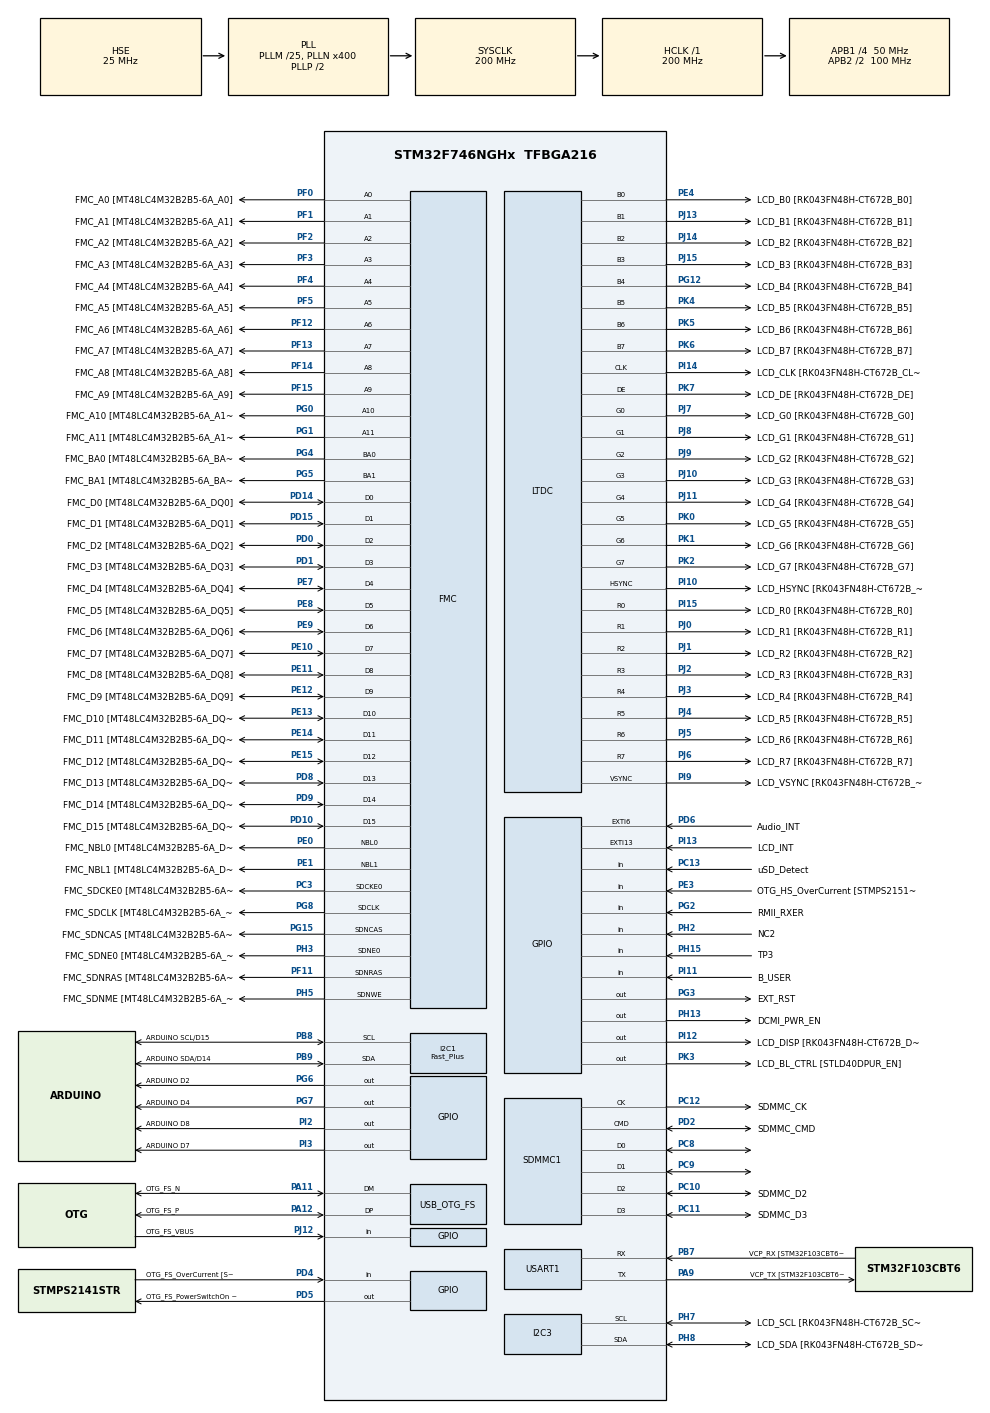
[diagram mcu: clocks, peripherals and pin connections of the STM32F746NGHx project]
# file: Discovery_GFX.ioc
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CORTEX_M7.ART_ACCLERATOR_ENABLE=1
CORTEX_M7.CPU_DCache=Enabled
CORTEX_M7.CPU_ICache=Enabled
CORTEX_M7.FlashInterface=TCM_Enabled
CORTEX_M7.PREFETCH_ENABLE=1
FATFS.BSP.number=1
FATFS._FS_EXFAT=1
FATFS._FS_NORTC=1
FATFS._LFN_UNICODE=0
FATFS._MAX_SS=4096
FATFS._NORTC_MDAY=1
FATFS._NORTC_MON=1
FATFS._NORTC_YEAR=2019
FATFS._STRF_ENCODE=0
FATFS._USE_EXPAND=1
FATFS._USE_FIND=1
FATFS._USE_FORWARD=1
FATFS._USE_LFN=3
FATFS._USE_MKFS=0
FATFS0.BSP.STBoard=false
FATFS0.BSP.api=Unknown
FATFS0.BSP.i2caddr=0
FATFS0.BSP.instance=PC13
FATFS0.BSP.ip=GPIO
FATFS0.BSP.mode=Input
FATFS0.BSP.name=Detect_SDIO
FATFS0.BSP.solution=PC13
FMC.CASLatency1=FMC_SDRAM_CAS_LATENCY_3
FMC.ExitSelfRefreshDelay1=7
FMC.LoadToActiveDelay1=2
FMC.RCDDelay1=2
FMC.RPDelay1=2
FMC.RPDelay2=2
FMC.ReadBurst1=FMC_SDRAM_RBURST_ENABLE
FMC.ReadBurst2=FMC_SDRAM_RBURST_ENABLE
FMC.RowCycleDelay1=6
FMC.RowCycleDelay2=6
FMC.SDClockPeriod1=FMC_SDRAM_CLOCK_PERIOD_2
FMC.SDClockPeriod2=FMC_SDRAM_CLOCK_PERIOD_2
FMC.SelfRefreshTime1=4
FMC.WriteRecoveryTime1=2
GRAPHICS.BSP.number=1
GRAPHICS.Check_OTM8009A_PixelFormat-STemWin=1
GRAPHICS.DMA2D_Graphics-STemWin=1
GRAPHICS.EA_1_Apptype=Window
GRAPHICS.EA_1_executable_name-STemWin=GUIBuilder.exe
GRAPHICS.GUI_NUM_LAYERS-STemWin=1
GRAPHICS.GUI_Num_KBYTES=64
GRAPHICS.GUI_RGB_ORDERING=ABGR
GRAPHICS.LIN_Color_Conversion_Layer0=GUICC_M8888I
GRAPHICS.LIN_Color_Conversion_Layer1=GUICC_M8888I
GRAPHICS.LIN_Color_Conversion_Layer1-STemWin=0
GRAPHICS.LIN_Frame_Buffer_Depth_Layer0-STemWin=32
GRAPHICS.LIN_Frame_Buffer_Depth_Layer1-STemWin=32
GRAPHICS.Num_MultBuffers=1
GRAPHICS.OPTIM_OS_use-STemWin=5
GRAPHICS.USE_Embedded_Wizard-STemWin=0
GRAPHICS.USE_STTouchGFX-STemWin=0
GRAPHICS.UseGUIBuilder=Enabled
GRAPHICS.Use_SDRAM-STemWin=SDRAM1_BANK1
GRAPHICS.Xsize_PHYS=480
GRAPHICS.Ysize_PHYS=272
GRAPHICS0.BSP.STBoard=false
GRAPHICS0.BSP.api=Unknown
GRAPHICS0.BSP.i2caddr=0
GRAPHICS0.BSP.instance=PG3
GRAPHICS0.BSP.ip=GPIO
GRAPHICS0.BSP.mode=Output
GRAPHICS0.BSP.name=LCD Reset Pin XRES
GRAPHICS0.BSP.solution=PG3
I2C1.I2C_Speed_Mode=I2C_Fast_Plus
I2C1.Timing=0x0020081F
I2C3.Timing=0x00C0EAFF
LTDC.ActiveH=272
LTDC.ActiveW=480
LTDC.Alpha_L0=255
LTDC.Alpha_L1=255
LTDC.BlendingFactor1_L0=LTDC_BLENDING_FACTOR1_PAxCA
LTDC.BlendingFactor1_L1=LTDC_BLENDING_FACTOR1_PAxCA
LTDC.BlendingFactor2_L0=LTDC_BLENDING_FACTOR2_PAxCA
LTDC.BlendingFactor2_L1=LTDC_BLENDING_FACTOR2_PAxCA
LTDC.FBStartAdress_L0=0xC0000000
LTDC.FBStartAdress_L1=0xC0100000
LTDC.HBP=13
LTDC.HFP=32
LTDC.HSync=41
LTDC.ImageHeight_L0=272
LTDC.ImageHeight_L1=272
LTDC.ImageWidth_L0=480
LTDC.ImageWidth_L1=480
LTDC.Layers=0
LTDC.PixelFormat_L0=LTDC_PIXEL_FORMAT_ARGB8888
LTDC.PixelFormat_L1=LTDC_PIXEL_FORMAT_ARGB8888
LTDC.VSync=10
LTDC.WindowX1_L0=480
LTDC.WindowX1_L1=480
LTDC.WindowY1_L0=272
LTDC.WindowY1_L1=272
Mcu.Family=STM32F7
Mcu.Name=STM32F746NGHx
Mcu.Package=TFBGA216
NVIC.DMA2D_IRQn=true\:1\:0\:true\:false\:true\:true\:true
NVIC.LTDC_IRQn=true\:2\:0\:true\:false\:true\:true\:true
NVIC.OTG_FS_IRQn=true\:7\:0\:true\:false\:true\:false\:true
NVIC.PriorityGroup=NVIC_PRIORITYGROUP_4
NVIC.SDMMC1_IRQn=true\:6\:0\:true\:false\:true\:true\:true
NVIC.TIM3_IRQn=true\:10\:0\:true\:false\:true\:true\:true
NVIC.TIM6_DAC_IRQn=true\:0\:0\:false\:false\:true\:false\:true
NVIC.TimeBase=TIM6_DAC_IRQn
NVIC.TimeBaseIP=TIM6
PA0/WKUP.GPIO_Label=ARDUINO A0
PA0/WKUP.GPIO_Mode=GPIO_MODE_ANALOG
PA0/WKUP.GPIO_PuPd=GPIO_NOPULL
PA0/WKUP.Signal=ADCx_IN0
PA1.GPIO_Label=RMII_REF_CLK [LAN8742A-CZ-TR_REFCLK0]
PA1.Signal=ETH_REF_CLK
PA10.GPIO_Label=OTG_FS_ID
PA10.Signal=USB_OTG_FS_ID
PA11.GPIO_Label=OTG_FS_N
PA11.Mode=Device_Only
PA11.Signal=USB_OTG_FS_DM
PA12.GPIO_Label=OTG_FS_P
PA12.Mode=Device_Only
PA12.Signal=USB_OTG_FS_DP
PA13.GPIO_Label=SWDIO
PA13.Mode=Serial_Wire
PA13.Signal=SYS_JTMS-SWDIO
PA14.GPIO_Label=SWCLK
PA14.Mode=Serial_Wire
PA14.Signal=SYS_JTCK-SWCLK
PA15.GPIO_Label=ARDUINO PWM/D9
PA15.GPIO_ModeDefaultPP=GPIO_MODE_AF_PP
PA15.GPIO_PuPd=GPIO_NOPULL
PA15.GPIO_Speed=GPIO_SPEED_FREQ_VERY_HIGH
PA15.Signal=S_TIM2_CH1_ETR
PA2.GPIO_Label=RMII_MDIO [LAN8742A-CZ-TR_MDIO]
PA2.Signal=ETH_MDIO
PA3.GPIO_Label=ULPI_D0 [USB3320C-EZK_D0]
PA3.Signal=USB_OTG_HS_ULPI_D0
PA4.GPIO_Label=DCMI_HSYNC
PA4.GPIO_Speed=GPIO_SPEED_FREQ_VERY_HIGH
PA4.Signal=DCMI_HSYNC
PA5.GPIO_Label=ULPI_CLK [USB3320C-EZK_CLKOUT]
PA5.Signal=USB_OTG_HS_ULPI_CK
PA6.GPIO_Speed=GPIO_SPEED_FREQ_VERY_HIGH
PA6.Signal=DCMI_PIXCLK
PA7.GPIO_Label=RMII_CRS_DV [LAN8742A-CZ-TR_CRS_DV]
PA7.Signal=ETH_CRS_DV
PA8.GPIO_Label=ARDUINO PWM/D10
PA8.GPIO_ModeDefaultPP=GPIO_MODE_AF_PP
PA8.GPIO_PuPd=GPIO_NOPULL
PA8.GPIO_Speed=GPIO_SPEED_FREQ_VERY_HIGH
PA8.Signal=S_TIM1_CH1
PA9.GPIO_Label=VCP_TX [STM32F103CBT6_PA3]
PA9.GPIO_Mode=GPIO_MODE_AF_PP
PA9.GPIO_PuPd=GPIO_NOPULL
PA9.GPIO_Speed=GPIO_SPEED_FREQ_LOW
PA9.Mode=Asynchronous
PA9.Signal=USART1_TX
PB0.GPIO_Label=ULPI_D1 [USB3320C-EZK_D1]
PB0.Signal=USB_OTG_HS_ULPI_D1
PB1.GPIO_Label=ULPI_D2 [USB3320C-EZK_D2]
PB1.Signal=USB_OTG_HS_ULPI_D2
PB10.GPIO_Label=ULPI_D3 [USB3320C-EZK_D3]
PB10.Signal=USB_OTG_HS_ULPI_D3
PB11.GPIO_Label=ULPI_D4 [USB3320C-EZK_D4]
PB11.Signal=USB_OTG_HS_ULPI_D4
PB12.GPIO_Label=ULPI_D5 [USB3320C-EZK_D5]
PB12.Signal=USB_OTG_HS_ULPI_D5
PB13.GPIO_Label=ULPI_D6 [USB3320C-EZK_D6]
PB13.Signal=USB_OTG_HS_ULPI_D6
PB14.GPIO_Label=ARDUINO MISO/D12
PB14.GPIO_Mode=GPIO_MODE_AF_PP
PB14.GPIO_PuPd=GPIO_NOPULL
PB14.GPIO_Speed=GPIO_SPEED_FREQ_LOW
PB14.Signal=SPI2_MISO
PB15.GPIO_Label=ARDUINO MOSI/PWM/D11
PB15.GPIO_Mode=GPIO_MODE_AF_PP
PB15.GPIO_PuPd=GPIO_NOPULL
PB15.GPIO_Speed=GPIO_SPEED_FREQ_LOW
PB15.Signal=SPI2_MOSI
PB2.Signal=QUADSPI_CLK
PB3.GPIO_Label=SWO
PB3.Signal=SYS_JTDO-SWO
PB4.GPIO_Label=ARDUINO PWM/D3
PB4.GPIO_ModeDefaultPP=GPIO_MODE_AF_PP
PB4.GPIO_PuPd=GPIO_NOPULL
PB4.GPIO_Speed=GPIO_SPEED_FREQ_LOW
PB4.Signal=S_TIM3_CH1
PB5.GPIO_Label=ULPI_D7 [USB3320C-EZK_D7]
PB5.Signal=USB_OTG_HS_ULPI_D7
PB6.GPIO_Label=QSPI_NCS [N25Q128A13EF840E_S]
PB6.Signal=QUADSPI_BK1_NCS
PB7.GPIO_Label=VCP_RX [STM32F103CBT6_PA2]
PB7.GPIO_Mode=GPIO_MODE_AF_PP
PB7.GPIO_PuPd=GPIO_NOPULL
PB7.GPIO_Speed=GPIO_SPEED_FREQ_LOW
PB7.Mode=Asynchronous
PB7.Signal=USART1_RX
PB8.GPIO_Label=ARDUINO SCL/D15
PB8.GPIO_Mode=GPIO_MODE_AF_OD
PB8.GPIO_PuPd=GPIO_NOPULL
PB8.GPIO_Speed=GPIO_SPEED_FREQ_LOW
PB8.Mode=I2C
PB8.Signal=I2C1_SCL
PB9.GPIO_Label=ARDUINO SDA/D14
PB9.GPIO_Mode=GPIO_MODE_AF_OD
PB9.GPIO_PuPd=GPIO_NOPULL
PB9.GPIO_Speed=GPIO_SPEED_FREQ_LOW
PB9.Mode=I2C
PB9.Signal=I2C1_SDA
PC0.GPIO_Label=ULPI_STP [USB3320C-EZK_STP]
PC0.Signal=USB_OTG_HS_ULPI_STP
PC1.GPIO_Label=RMII_MDC [LAN8742A-CZ-TR_MDC]
PC1.Signal=ETH_MDC
PC10.GPIO_Label=SDMMC_D2
PC10.Mode=SD_4_bits_Wide_bus
PC10.Signal=SDMMC1_D2
PC11.GPIO_Label=SDMMC_D3
PC11.Mode=SD_4_bits_Wide_bus
PC11.Signal=SDMMC1_D3
PC12.GPIO_Label=SDMMC_CK
PC12.Mode=SD_4_bits_Wide_bus
PC12.Signal=SDMMC1_CK
PC13.GPIO_Label=uSD_Detect
PC13.Signal=GPIO_Input
PC14/OSC32_IN.GPIO_Label=RCC_OSC32_IN
PC14/OSC32_IN.Signal=RCC_OSC32_IN
PC15/OSC32_OUT.GPIO_Label=RCC_OSC32_OUT
PC15/OSC32_OUT.Signal=RCC_OSC32_OUT
PC2.GPIO_Label=ULPI_DIR [USB3320C-EZK_DIR]
PC2.Signal=USB_OTG_HS_ULPI_DIR
PC3.GPIO_Label=FMC_SDCKE0 [MT48LC4M32B2B5-6A_CKE]
PC3.Mode=SdramChipSelect1_1
PC3.Signal=FMC_SDCKE0
PC4.GPIO_Label=RMII_RXD0 [LAN8742A-CZ-TR_RXD0]
PC4.Signal=ETH_RXD0
PC5.GPIO_Label=RMII_RXD1 [LAN8742A-CZ-TR_RXD1]
PC5.Signal=ETH_RXD1
PC6.GPIO_Label=ARDUINO TX/D1
PC6.Signal=USART6_TX
PC7.GPIO_Label=ARDUINO RX/D0
PC7.Signal=USART6_RX
PC8.Mode=SD_4_bits_Wide_bus
PC8.Signal=SDMMC1_D0
PC9.Mode=SD_4_bits_Wide_bus
PC9.Signal=SDMMC1_D1
PD0.GPIO_Label=FMC_D2 [MT48LC4M32B2B5-6A_DQ2]
PD0.Signal=FMC_D2_DA2
PD1.GPIO_Label=FMC_D3 [MT48LC4M32B2B5-6A_DQ3]
PD1.Signal=FMC_D3_DA3
PD10.GPIO_Label=FMC_D15 [MT48LC4M32B2B5-6A_DQ15]
PD10.Signal=FMC_D15_DA15
PD11.GPIO_Label=QSPI_D0 [N25Q128A13EF840E_DQ0]
PD11.Signal=QUADSPI_BK1_IO0
PD12.GPIO_Label=QSPI_D1 [N25Q128A13EF840E_DQ1]
PD12.Signal=QUADSPI_BK1_IO1
PD13.GPIO_Label=QSPI_D3 [N25Q128A13EF840E_DQ3]
PD13.Signal=QUADSPI_BK1_IO3
PD14.GPIO_Label=FMC_D0 [MT48LC4M32B2B5-6A_DQ0]
PD14.Signal=FMC_D0_DA0
PD15.GPIO_Label=FMC_D1 [MT48LC4M32B2B5-6A_DQ1]
PD15.Signal=FMC_D1_DA1
PD2.GPIO_Label=SDMMC_CMD
PD2.Mode=SD_4_bits_Wide_bus
PD2.Signal=SDMMC1_CMD
PD3.GPIO_Label=DCMI_D5
PD3.GPIO_Speed=GPIO_SPEED_FREQ_VERY_HIGH
PD3.Signal=DCMI_D5
PD4.GPIO_Label=OTG_FS_OverCurrent [STMPS2141STR_Fault]
PD4.Signal=GPIO_Input
PD5.GPIO_Label=OTG_FS_PowerSwitchOn [STMPS2141STR_EN]
PD5.PinState=GPIO_PIN_SET
PD5.Signal=GPIO_Output
PD6.GPIO_Label=Audio_INT
PD6.GPIO_ModeDefaultEXTI=GPIO_MODE_EVT_RISING
PD6.Signal=GPXTI6
PD7.GPIO_Label=SPDIF_RX0 [74LVC1G04SE_4]
PD7.Signal=SPDIFRX_IN0
PD8.GPIO_Label=FMC_D13 [MT48LC4M32B2B5-6A_DQ13]
PD8.Signal=FMC_D13_DA13
PD9.GPIO_Label=FMC_D14 [MT48LC4M32B2B5-6A_DQ14]
PD9.Signal=FMC_D14_DA14
PE0.GPIO_Label=FMC_NBL0 [MT48LC4M32B2B5-6A_DQM0]
PE0.Signal=FMC_NBL0
PE1.GPIO_Label=FMC_NBL1 [MT48LC4M32B2B5-6A_DQM1]
PE1.Signal=FMC_NBL1
PE10.GPIO_Label=FMC_D7 [MT48LC4M32B2B5-6A_DQ7]
PE10.Signal=FMC_D7_DA7
PE11.GPIO_Label=FMC_D8 [MT48LC4M32B2B5-6A_DQ8]
PE11.Signal=FMC_D8_DA8
PE12.GPIO_Label=FMC_D9 [MT48LC4M32B2B5-6A_DQ9]
PE12.Signal=FMC_D9_DA9
PE13.GPIO_Label=FMC_D10 [MT48LC4M32B2B5-6A_DQ10]
PE13.Signal=FMC_D10_DA10
PE14.GPIO_Label=FMC_D11 [MT48LC4M32B2B5-6A_DQ11]
PE14.Signal=FMC_D11_DA11
PE15.GPIO_Label=FMC_D12 [MT48LC4M32B2B5-6A_DQ12]
PE15.Signal=FMC_D12_DA12
PE2.GPIO_Label=QSPI_D2 [N25Q128A13EF840E_DQ2]
PE2.Signal=QUADSPI_BK1_IO2
PE3.GPIO_Label=OTG_HS_OverCurrent [STMPS2151STR_FAULT]
PE3.Signal=GPIO_Input
PE4.GPIO_Label=LCD_B0 [RK043FN48H-CT672B_B0]
PE4.GPIO_Speed=GPIO_SPEED_FREQ_VERY_HIGH
PE4.Mode=RGB888
PE4.Signal=LTDC_B0
PE5.GPIO_Label=DCMI_D6
PE5.GPIO_Speed=GPIO_SPEED_FREQ_VERY_HIGH
PE5.Signal=DCMI_D6
PE6.GPIO_Label=DCMI_D7
PE6.GPIO_Speed=GPIO_SPEED_FREQ_VERY_HIGH
PE6.Signal=DCMI_D7
PE7.GPIO_Label=FMC_D4 [MT48LC4M32B2B5-6A_DQ4]
PE7.Signal=FMC_D4_DA4
PE8.GPIO_Label=FMC_D5 [MT48LC4M32B2B5-6A_DQ5]
PE8.Signal=FMC_D5_DA5
PE9.GPIO_Label=FMC_D6 [MT48LC4M32B2B5-6A_DQ6]
PE9.Signal=FMC_D6_DA6
PF0.GPIO_Label=FMC_A0 [MT48LC4M32B2B5-6A_A0]
PF0.Signal=FMC_A0
PF1.GPIO_Label=FMC_A1 [MT48LC4M32B2B5-6A_A1]
PF1.Signal=FMC_A1
PF10.GPIO_Label=ARDUINO A1
PF10.GPIO_Mode=GPIO_MODE_ANALOG
PF10.GPIO_PuPd=GPIO_NOPULL
PF10.Signal=ADC3_IN8
PF11.GPIO_Label=FMC_SDNRAS [MT48LC4M32B2B5-6A_RAS]
PF11.Signal=FMC_SDNRAS
PF12.GPIO_Label=FMC_A6 [MT48LC4M32B2B5-6A_A6]
PF12.Signal=FMC_A6
PF13.GPIO_Label=FMC_A7 [MT48LC4M32B2B5-6A_A7]
PF13.Signal=FMC_A7
PF14.GPIO_Label=FMC_A8 [MT48LC4M32B2B5-6A_A8]
PF14.Signal=FMC_A8
PF15.GPIO_Label=FMC_A9 [MT48LC4M32B2B5-6A_A9]
PF15.Signal=FMC_A9
PF2.GPIO_Label=FMC_A2 [MT48LC4M32B2B5-6A_A2]
PF2.Signal=FMC_A2
PF3.GPIO_Label=FMC_A3 [MT48LC4M32B2B5-6A_A3]
PF3.Signal=FMC_A3
PF4.GPIO_Label=FMC_A4 [MT48LC4M32B2B5-6A_A4]
PF4.Signal=FMC_A4
PF5.GPIO_Label=FMC_A5 [MT48LC4M32B2B5-6A_A5]
PF5.Signal=FMC_A5
PF6.GPIO_Label=ARDUINO A5
PF6.GPIO_Mode=GPIO_MODE_ANALOG
PF6.GPIO_PuPd=GPIO_NOPULL
PF6.Signal=ADC3_IN4
PF7.GPIO_Label=ARDUINO A4
PF7.GPIO_Mode=GPIO_MODE_ANALOG
PF7.GPIO_PuPd=GPIO_NOPULL
PF7.Signal=ADC3_IN5
PF8.GPIO_Label=ARDUINO A3
PF8.GPIO_Mode=GPIO_MODE_ANALOG
PF8.GPIO_PuPd=GPIO_NOPULL
PF8.Signal=ADC3_IN6
PF9.GPIO_Label=ARDUINO A2
PF9.GPIO_Mode=GPIO_MODE_ANALOG
PF9.GPIO_PuPd=GPIO_NOPULL
PF9.Signal=ADC3_IN7
PG0.GPIO_Label=FMC_A10 [MT48LC4M32B2B5-6A_A10]
PG0.Signal=FMC_A10
PG1.GPIO_Label=FMC_A11 [MT48LC4M32B2B5-6A_A11]
PG1.Signal=FMC_A11
PG10.GPIO_Label=SAI2_SDB [WM8994ECS/R_ADCDAT1]
PG10.Signal=SAI2_SD_B
PG11.GPIO_Label=RMII_TX_EN [LAN8742A-CZ-TR_TXEN]
PG11.Signal=ETH_TX_EN
PG12.GPIO_Label=LCD_B4 [RK043FN48H-CT672B_B4]
PG12.GPIO_Speed=GPIO_SPEED_FREQ_VERY_HIGH
PG12.Mode=RGB888
PG12.Signal=LTDC_B4
PG13.GPIO_Label=RMII_TXD0 [LAN8742A-CZ-TR_TXD0]
PG13.Signal=ETH_TXD0
PG14.GPIO_Label=RMII_TXD1 [LAN8742A-CZ-TR_TXD1]
PG14.Signal=ETH_TXD1
PG15.GPIO_Label=FMC_SDNCAS [MT48LC4M32B2B5-6A_CAS]
PG15.Signal=FMC_SDNCAS
PG2.GPIO_Label=RMII_RXER
PG2.Signal=GPIO_Input
PG3.GPIO_Label=EXT_RST
PG3.Signal=GPIO_Output
PG4.GPIO_Label=FMC_BA0 [MT48LC4M32B2B5-6A_BA0]
PG4.Signal=FMC_A14_BA0
PG5.GPIO_Label=FMC_BA1 [MT48LC4M32B2B5-6A_BA1]
PG5.Signal=FMC_A15_BA1
PG6.GPIO_Label=ARDUINO D2
PG6.Signal=GPIO_Output
PG7.GPIO_Label=ARDUINO D4
PG7.Signal=GPIO_Output
PG8.GPIO_Label=FMC_SDCLK [MT48LC4M32B2B5-6A_CLK]
PG8.Signal=FMC_SDCLK
PG9.GPIO_Label=DCMI_VSYNC
PG9.GPIO_Speed=GPIO_SPEED_FREQ_VERY_HIGH
PG9.Signal=DCMI_VSYNC
PH0/OSC_IN.GPIO_Label=OSC_25M [NZ2520SB-25.00M_OUT]
PH0/OSC_IN.Mode=HSE-External-Oscillator
PH0/OSC_IN.Signal=RCC_OSC_IN
PH1/OSC_OUT.Mode=HSE-External-Oscillator
PH1/OSC_OUT.Signal=RCC_OSC_OUT
PH10.GPIO_Label=DCMI_D1
PH10.GPIO_Speed=GPIO_SPEED_FREQ_VERY_HIGH
PH10.Signal=DCMI_D1
PH11.GPIO_Label=DCMI_D2
PH11.GPIO_Speed=GPIO_SPEED_FREQ_VERY_HIGH
PH11.Signal=DCMI_D2
PH12.GPIO_Label=DCMI_D3
PH12.GPIO_Speed=GPIO_SPEED_FREQ_VERY_HIGH
PH12.Signal=DCMI_D3
PH13.GPIO_Label=DCMI_PWR_EN
PH13.Signal=GPIO_Output
PH14.GPIO_Label=DCMI_D4
PH14.GPIO_Speed=GPIO_SPEED_FREQ_VERY_HIGH
PH14.Signal=DCMI_D4
PH15.GPIO_Label=TP3
PH15.Signal=GPIO_Input
PH2.GPIO_Label=NC2
PH2.Signal=GPIO_Input
PH3.GPIO_Label=FMC_SDNE0 [MT48LC4M32B2B5-6A_CS]
PH3.Mode=SdramChipSelect1_1
PH3.Signal=FMC_SDNE0
PH4.GPIO_Label=ULPI_NXT [USB3320C-EZK_NXT]
PH4.Signal=USB_OTG_HS_ULPI_NXT
PH5.GPIO_Label=FMC_SDNME [MT48LC4M32B2B5-6A_WE]
PH5.Signal=FMC_SDNWE
PH6.GPIO_Label=ARDUINO PWM/D6
PH6.Signal=S_TIM12_CH1
PH7.GPIO_Label=LCD_SCL [RK043FN48H-CT672B_SCL]
PH7.Mode=I2C
PH7.Signal=I2C3_SCL
PH8.GPIO_Label=LCD_SDA [RK043FN48H-CT672B_SDA]
PH8.Mode=I2C
PH8.Signal=I2C3_SDA
PH9.GPIO_Label=DCMI_D0
PH9.GPIO_Speed=GPIO_SPEED_FREQ_VERY_HIGH
PH9.Signal=DCMI_D0
PI0.GPIO_Label=ARDUINO PWM/CS/D5
PI0.GPIO_ModeDefaultPP=GPIO_MODE_AF_PP
PI0.GPIO_PuPd=GPIO_NOPULL
PI0.GPIO_Speed=GPIO_SPEED_FREQ_LOW
PI0.Signal=S_TIM5_CH4
PI1.GPIO_Label=ARDUINO SCK/D13
PI1.GPIO_Mode=GPIO_MODE_AF_PP
PI1.GPIO_PuPd=GPIO_NOPULL
PI1.GPIO_Speed=GPIO_SPEED_FREQ_LOW
PI1.Signal=SPI2_SCK
PI10.GPIO_Label=LCD_HSYNC [RK043FN48H-CT672B_HSYNC]
PI10.GPIO_Speed=GPIO_SPEED_FREQ_VERY_HIGH
PI10.Mode=RGB888
PI10.Signal=LTDC_HSYNC
PI11.GPIO_Label=B_USER
PI11.Signal=GPIO_Input
PI12.GPIO_Label=LCD_DISP [RK043FN48H-CT672B_DISP] 
PI12.PinState=GPIO_PIN_SET
PI12.Signal=GPIO_Output
PI13.GPIO_Label=LCD_INT
PI13.GPIO_ModeDefaultEXTI=GPIO_MODE_EVT_RISING
PI13.Signal=GPXTI13
PI14.GPIO_Label=LCD_CLK [RK043FN48H-CT672B_CLK]
PI14.GPIO_Speed=GPIO_SPEED_FREQ_VERY_HIGH
PI14.Mode=RGB888
PI14.Signal=LTDC_CLK
PI15.GPIO_Label=LCD_R0 [RK043FN48H-CT672B_R0]
PI15.GPIO_Speed=GPIO_SPEED_FREQ_VERY_HIGH
PI15.Mode=RGB888
PI15.Signal=LTDC_R0
PI2.GPIO_Label=ARDUINO D8
PI2.Signal=GPIO_Output
PI3.GPIO_Label=ARDUINO D7
PI3.Signal=GPIO_Output
PI4.GPIO_Label=SAI2_MCLKA [WM8994ECS/R_MCLK1]
PI4.Signal=SAI2_MCLK_A
PI5.GPIO_Label=SAI2_SCKA [WM8994ECS/R_BCLK1]
PI5.Signal=SAI2_SCK_A
PI6.GPIO_Label=SAI2_SDA [WM8994ECS/R_DACDAT1]
PI6.Signal=SAI2_SD_A
PI7.GPIO_Label=SAI2_FSA [WM8994ECS/R_LRCLK1]
PI7.Signal=SAI2_FS_A
PI8.GPIO_Label=NC1 [TP2]
PI8.Signal=RTC_TS
PI9.GPIO_Label=LCD_VSYNC [RK043FN48H-CT672B_VSYNC]
PI9.GPIO_Speed=GPIO_SPEED_FREQ_VERY_HIGH
PI9.Mode=RGB888
PI9.Signal=LTDC_VSYNC
PJ0.GPIO_Label=LCD_R1 [RK043FN48H-CT672B_R1]
PJ0.GPIO_Speed=GPIO_SPEED_FREQ_VERY_HIGH
PJ0.Mode=RGB888
PJ0.Signal=LTDC_R1
PJ1.GPIO_Label=LCD_R2 [RK043FN48H-CT672B_R2]
PJ1.GPIO_Speed=GPIO_SPEED_FREQ_VERY_HIGH
PJ1.Mode=RGB888
PJ1.Signal=LTDC_R2
PJ10.GPIO_Label=LCD_G3 [RK043FN48H-CT672B_G3]
PJ10.GPIO_Speed=GPIO_SPEED_FREQ_VERY_HIGH
PJ10.Mode=RGB888
PJ10.Signal=LTDC_G3
PJ11.GPIO_Label=LCD_G4 [RK043FN48H-CT672B_G4]
PJ11.GPIO_Speed=GPIO_SPEED_FREQ_VERY_HIGH
PJ11.Mode=RGB888
PJ11.Signal=LTDC_G4
PJ12.GPIO_Label=OTG_FS_VBUS
PJ12.Signal=GPIO_Input
PJ13.GPIO_Label=LCD_B1 [RK043FN48H-CT672B_B1]
PJ13.GPIO_Speed=GPIO_SPEED_FREQ_VERY_HIGH
PJ13.Mode=RGB888
PJ13.Signal=LTDC_B1
PJ14.GPIO_Label=LCD_B2 [RK043FN48H-CT672B_B2]
PJ14.GPIO_Speed=GPIO_SPEED_FREQ_VERY_HIGH
PJ14.Mode=RGB888
PJ14.Signal=LTDC_B2
PJ15.GPIO_Label=LCD_B3 [RK043FN48H-CT672B_B3]
PJ15.GPIO_Speed=GPIO_SPEED_FREQ_VERY_HIGH
PJ15.Mode=RGB888
PJ15.Signal=LTDC_B3
PJ2.GPIO_Label=LCD_R3 [RK043FN48H-CT672B_R3]
PJ2.GPIO_Speed=GPIO_SPEED_FREQ_VERY_HIGH
PJ2.Mode=RGB888
PJ2.Signal=LTDC_R3
PJ3.GPIO_Label=LCD_R4 [RK043FN48H-CT672B_R4]
PJ3.GPIO_Speed=GPIO_SPEED_FREQ_VERY_HIGH
PJ3.Mode=RGB888
PJ3.Signal=LTDC_R4
PJ4.GPIO_Label=LCD_R5 [RK043FN48H-CT672B_R5]
PJ4.GPIO_Speed=GPIO_SPEED_FREQ_VERY_HIGH
PJ4.Mode=RGB888
PJ4.Signal=LTDC_R5
PJ5.GPIO_Label=LCD_R6 [RK043FN48H-CT672B_R6]
PJ5.GPIO_Speed=GPIO_SPEED_FREQ_VERY_HIGH
PJ5.Mode=RGB888
PJ5.Signal=LTDC_R6
PJ6.GPIO_Label=LCD_R7 [RK043FN48H-CT672B_R7]
PJ6.GPIO_Speed=GPIO_SPEED_FREQ_VERY_HIGH
PJ6.Mode=RGB888
PJ6.Signal=LTDC_R7
PJ7.GPIO_Label=LCD_G0 [RK043FN48H-CT672B_G0]
PJ7.GPIO_Speed=GPIO_SPEED_FREQ_VERY_HIGH
PJ7.Mode=RGB888
PJ7.Signal=LTDC_G0
PJ8.GPIO_Label=LCD_G1 [RK043FN48H-CT672B_G1]
PJ8.GPIO_Speed=GPIO_SPEED_FREQ_VERY_HIGH
PJ8.Mode=RGB888
PJ8.Signal=LTDC_G1
PJ9.GPIO_Label=LCD_G2 [RK043FN48H-CT672B_G2]
PJ9.GPIO_Speed=GPIO_SPEED_FREQ_VERY_HIGH
PJ9.Mode=RGB888
PJ9.Signal=LTDC_G2
PK0.GPIO_Label=LCD_G5 [RK043FN48H-CT672B_G5]
PK0.GPIO_Speed=GPIO_SPEED_FREQ_VERY_HIGH
PK0.Mode=RGB888
PK0.Signal=LTDC_G5
PK1.GPIO_Label=LCD_G6 [RK043FN48H-CT672B_G6]
PK1.GPIO_Speed=GPIO_SPEED_FREQ_VERY_HIGH
PK1.Mode=RGB888
PK1.Signal=LTDC_G6
PK2.GPIO_Label=LCD_G7 [RK043FN48H-CT672B_G7]
PK2.GPIO_Speed=GPIO_SPEED_FREQ_VERY_HIGH
PK2.Mode=RGB888
PK2.Signal=LTDC_G7
PK3.GPIO_Label=LCD_BL_CTRL [STLD40DPUR_EN]
PK3.GPIO_Speed=GPIO_SPEED_FREQ_LOW
PK3.PinState=GPIO_PIN_SET
PK3.Signal=GPIO_Output
PK4.GPIO_Label=LCD_B5 [RK043FN48H-CT672B_B5]
PK4.GPIO_Speed=GPIO_SPEED_FREQ_VERY_HIGH
PK4.Mode=RGB888
PK4.Signal=LTDC_B5
PK5.GPIO_Label=LCD_B6 [RK043FN48H-CT672B_B6]
PK5.GPIO_Speed=GPIO_SPEED_FREQ_VERY_HIGH
PK5.Mode=RGB888
PK5.Signal=LTDC_B6
PK6.GPIO_Label=LCD_B7 [RK043FN48H-CT672B_B7]
PK6.GPIO_Speed=GPIO_SPEED_FREQ_VERY_HIGH
PK6.Mode=RGB888
PK6.Signal=LTDC_B7
PK7.GPIO_Label=LCD_DE [RK043FN48H-CT672B_DE]
PK7.GPIO_Speed=GPIO_SPEED_FREQ_VERY_HIGH
PK7.Mode=RGB888
PK7.Signal=LTDC_DE
ProjectManager.HeapSize=0x4000
ProjectManager.StackSize=0x4000
ProjectManager.TargetToolchain=EWARM V8
RCC.AHBFreq_Value=200000000
RCC.APB1CLKDivider=RCC_HCLK_DIV4
RCC.APB1Freq_Value=50000000
RCC.APB1TimFreq_Value=100000000
RCC.APB2CLKDivider=RCC_HCLK_DIV2
RCC.APB2Freq_Value=100000000
RCC.APB2TimFreq_Value=200000000
RCC.CortexFreq_Value=200000000
RCC.HCLKFreq_Value=200000000
RCC.HSE_VALUE=25000000
RCC.HSI_VALUE=16000000
RCC.LSE_VALUE=32768
RCC.PLL48CLockSelection=RCC_CLK48SOURCE_PLLSAIP
RCC.PLLI2SN=100
RCC.PLLM=25
RCC.PLLN=400
RCC.PLLQ=9
RCC.PLLSAIP=RCC_PLLSAIP_DIV4
RCC.PLLSAIR=6
RCC.PLLSAIRDiv=RCC_PLLSAIDIVR_4
RCC.SDMMCClockSelection=RCC_SDMMC1CLKSOURCE_CLK48
RCC.SYSCLKFreq_VALUE=200000000
RCC.SYSCLKSource=RCC_SYSCLKSOURCE_PLLCLK
RCC.USBFreq_Value=48000000
RCC.VCOOutputFreq_Value=400000000
SDMMC1.ClockDiv=0
SDMMC1.HardwareFlowControl=SDMMC_HARDWARE_FLOW_CONTROL_ENABLE
SH.ADCx_IN0.0=ADC3_IN0
SH.FMC_A0.0=FMC_A0,12b-sda1
SH.FMC_A1.0=FMC_A1,12b-sda1
SH.FMC_A10.0=FMC_A10,12b-sda1
SH.FMC_A11.0=FMC_A11,12b-sda1
SH.FMC_A14_BA0.0=FMC_BA0,FourSdramBanks1
SH.FMC_A15_BA1.0=FMC_BA1,FourSdramBanks1
SH.FMC_A2.0=FMC_A2,12b-sda1
SH.FMC_A3.0=FMC_A3,12b-sda1
SH.FMC_A4.0=FMC_A4,12b-sda1
SH.FMC_A5.0=FMC_A5,12b-sda1
SH.FMC_A6.0=FMC_A6,12b-sda1
SH.FMC_A7.0=FMC_A7,12b-sda1
SH.FMC_A8.0=FMC_A8,12b-sda1
SH.FMC_A9.0=FMC_A9,12b-sda1
SH.FMC_D0_DA0.0=FMC_D0,sd-16b-d1
SH.FMC_D10_DA10.0=FMC_D10,sd-16b-d1
SH.FMC_D11_DA11.0=FMC_D11,sd-16b-d1
SH.FMC_D12_DA12.0=FMC_D12,sd-16b-d1
SH.FMC_D13_DA13.0=FMC_D13,sd-16b-d1
SH.FMC_D14_DA14.0=FMC_D14,sd-16b-d1
SH.FMC_D15_DA15.0=FMC_D15,sd-16b-d1
SH.FMC_D1_DA1.0=FMC_D1,sd-16b-d1
SH.FMC_D2_DA2.0=FMC_D2,sd-16b-d1
SH.FMC_D3_DA3.0=FMC_D3,sd-16b-d1
SH.FMC_D4_DA4.0=FMC_D4,sd-16b-d1
SH.FMC_D5_DA5.0=FMC_D5,sd-16b-d1
SH.FMC_D6_DA6.0=FMC_D6,sd-16b-d1
SH.FMC_D7_DA7.0=FMC_D7,sd-16b-d1
SH.FMC_D8_DA8.0=FMC_D8,sd-16b-d1
SH.FMC_D9_DA9.0=FMC_D9,sd-16b-d1
SH.FMC_NBL0.0=FMC_NBL0,Sd2ByteEnable1
SH.FMC_NBL1.0=FMC_NBL1,Sd2ByteEnable1
SH.FMC_SDCLK.0=FMC_SDCLK,12b-sda1
SH.FMC_SDNCAS.0=FMC_SDNCAS,12b-sda1
SH.FMC_SDNRAS.0=FMC_SDNRAS,12b-sda1
SH.FMC_SDNWE.0=FMC_SDNWE,12b-sda1
SH.S_TIM12_CH1.0=TIM12_CH1
SH.S_TIM1_CH1.0=TIM1_CH1
SH.S_TIM2_CH1_ETR.0=TIM2_CH1
SH.S_TIM3_CH1.0=TIM3_CH1
SH.S_TIM5_CH4.0=TIM5_CH4
TIM3.Period=499
TIM3.Prescaler=8999
USART1.VirtualMode-Asynchronous=VM_ASYNC
USB_DEVICE.CLASS_NAME_FS=MSC
USB_DEVICE.MSC_MEDIA_PACKET-MSC_FS=8192
USB_DEVICE.USBD_LPM_ENABLED-MSC_FS=0
USB_DEVICE.VirtualMode-MSC_FS=Msc
USB_DEVICE.VirtualModeFS=Msc_FS
USB_OTG_FS.VirtualMode=Device_Only
VP_CRC_VS_CRC.Mode=CRC_Activate
VP_DMA2D_VS_DMA2D.Mode=DMA2D_Activate
VP_FATFS_VS_SDIO.Mode=SDIO
VP_GRAPHICS_VS-DisplayInterface-LTDC.Mode=Display Parallel Interface using LTDC
VP_GRAPHICS_VS-STemWin.Mode=STemWin
VP_SYS_VS_tim6.Mode=TIM6
VP_TIM3_VS_ClockSourceITR.Mode=TriggerSource_ITR0
VP_TIM3_VS_ControllerModeReset.Mode=Reset Mode
VP_USB_DEVICE_VS_USB_DEVICE_MSC_FS.Mode=MSC_FS
board=32F746GDISCOVERY

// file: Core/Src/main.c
/* USER CODE BEGIN Header */
/**
  ******************************************************************************
  * @file           : main.c
  * @brief          : Main program body
  ******************************************************************************
  * This notice applies to any and all portions of this file
  * that are not between comment pairs USER CODE BEGIN and
  * USER CODE END. Other portions of this file, whether
  * inserted by the user or by software development tools
  * are owned by their respective copyright owners.
  *
  * Copyright (c) 2019 STMicroelectronics International N.V.
  * All rights reserved.
  *
  * Redistribution and use in source and binary forms, with or without
  * modification, are permitted, provided that the following conditions are met:
  *
  * 1. Redistribution of source code must retain the above copyright notice,
  *    this list of conditions and the following disclaimer.
  * 2. Redistributions in binary form must reproduce the above copyright notice,
  *    this list of conditions and the following disclaimer in the documentation
  *    and/or other materials provided with the distribution.
  * 3. Neither the name of STMicroelectronics nor the names of other
  *    contributors to this software may be used to endorse or promote products
  *    derived from this software without specific written permission.
  * 4. This software, including modifications and/or derivative works of this
  *    software, must execute solely and exclusively on microcontroller or
  *    microprocessor devices manufactured by or for STMicroelectronics.
  * 5. Redistribution and use of this software other than as permitted under
  *    this license is void and will automatically terminate your rights under
  *    this license.
  *
  * THIS SOFTWARE IS PROVIDED BY STMICROELECTRONICS AND CONTRIBUTORS "AS IS"
  * AND ANY EXPRESS, IMPLIED OR STATUTORY WARRANTIES, INCLUDING, BUT NOT
  * LIMITED TO, THE IMPLIED WARRANTIES OF MERCHANTABILITY, FITNESS FOR A
  * PARTICULAR PURPOSE AND NON-INFRINGEMENT OF THIRD PARTY INTELLECTUAL PROPERTY
  * RIGHTS ARE DISCLAIMED TO THE FULLEST EXTENT PERMITTED BY LAW. IN NO EVENT
  * SHALL STMICROELECTRONICS OR CONTRIBUTORS BE LIABLE FOR ANY DIRECT, INDIRECT,
  * INCIDENTAL, SPECIAL, EXEMPLARY, OR CONSEQUENTIAL DAMAGES (INCLUDING, BUT NOT
  * LIMITED TO, PROCUREMENT OF SUBSTITUTE GOODS OR SERVICES; LOSS OF USE, DATA,
  * OR PROFITS; OR BUSINESS INTERRUPTION) HOWEVER CAUSED AND ON ANY THEORY OF
  * LIABILITY, WHETHER IN CONTRACT, STRICT LIABILITY, OR TORT (INCLUDING
  * NEGLIGENCE OR OTHERWISE) ARISING IN ANY WAY OUT OF THE USE OF THIS SOFTWARE,
  * EVEN IF ADVISED OF THE POSSIBILITY OF SUCH DAMAGE.
  *
  ******************************************************************************
  */
/* USER CODE END Header */

#include "main.h"
#include "fatfs.h"
#include "usb_device.h"

/* USER CODE BEGIN Includes */
#include "stdio.h"
#include "stdlib.h"
#include "string.h"

#include "stm32746g_discovery.h"
#include "stm32746g_discovery_ts.h"

#include "usbd_core.h"

#include "WM.h"
#include "DIALOG.h"

#include "MLX90640_API.h"

#include "bme280.h"

/* USER CODE END Includes */

CRC_HandleTypeDef hcrc;

I2C_HandleTypeDef hi2c1;
I2C_HandleTypeDef hi2c3;

SD_HandleTypeDef hsd1;

TIM_HandleTypeDef htim3;

UART_HandleTypeDef huart1;

void SystemClock_Config(void);
static void MX_GPIO_Init(void);
static void MX_CRC_Init(void);
extern void GRAPHICS_HW_Init(void);
extern void GRAPHICS_Init(void);
extern void GRAPHICS_MainTask(void);
static void MX_I2C1_Init(void);
static void MX_TIM3_Init(void);
static void MX_USART1_UART_Init(void);
static void MX_I2C3_Init(void);
static void MX_SDMMC1_SD_Init(void);

/* USER CODE BEGIN 0 */

#define ADDR_FLASH_SECTOR_0     ((uint32_t)0x08000000) /* Base address of Sector 0, 32 Kbytes */
#define ADDR_FLASH_SECTOR_1     ((uint32_t)0x08008000) /* Base address of Sector 1, 32 Kbytes */
#define ADDR_FLASH_SECTOR_2     ((uint32_t)0x08010000) /* Base address of Sector 2, 32 Kbytes */
#define ADDR_FLASH_SECTOR_3     ((uint32_t)0x08018000) /* Base address of Sector 3, 32 Kbytes */
#define ADDR_FLASH_SECTOR_4     ((uint32_t)0x08020000) /* Base address of Sector 4, 128 Kbytes */
#define ADDR_FLASH_SECTOR_5     ((uint32_t)0x08040000) /* Base address of Sector 5, 256 Kbytes */
#define ADDR_FLASH_SECTOR_6     ((uint32_t)0x08080000) /* Base address of Sector 6, 256 Kbytes */
#define ADDR_FLASH_SECTOR_7     ((uint32_t)0x080C0000) /* Base address of Sector 7, 256 Kbytes */
#define FLASH_USER_START_ADDR   ADDR_FLASH_SECTOR_7   /* Start @ of user Flash area */

#define SDRAM_ADDR_START_VALS 0xC0400000
#define SDRAM_ADDR_START_SCREENSHOT 0xC0300000
#define SDRAM_ADDR_START_SCALE 0xC0500000

//

WM_HWIN CreateWindow(void);

//

extern LTDC_HandleTypeDef hltdc;
extern USBD_HandleTypeDef hUsbDeviceFS;
HAL_SD_CardInfoTypeDef SDCardInfo;
HAL_SD_CardStateTypeDef SDCardState;

FATFS fileSystem;
FRESULT fr;
FIL file;
FILINFO fno;
char last_name[40];

TS_StateTypeDef ts;
static GUI_PID_STATE TS_State;

uint32_t layer0_StartAddr = 0;
uint32_t layer1_StartAddr = 0;

uint8_t _acBuffer[4096];

uint8_t SD_busy = 0;

char str[40] = {0};

const uint16_t start_x = 120;
const uint16_t start_y = 0;

const float sq_size_xy_orig = 11.25f;

uint16_t watch_x = 0;
uint16_t watch_y = 0;

void temp_setlabel(char *str);

//

uint8_t scan_enabled = 1;
uint8_t need_to_clear = 0;
uint8_t need_to_redraw = 0;
uint8_t need_to_save = 0;
uint8_t need_to_cfg = 0;
uint8_t need_to_cfg_scale = 0;

//

#define  FPS2HZ   0x02
#define  FPS4HZ   0x03
#define  FPS8HZ   0x04
#define  FPS16HZ  0x05
#define  FPS32HZ  0x06

#define  MLX90640_ADDR 0x33
#define  TA_SHIFT 8

paramsMLX90640 mlx90640;
uint16_t eeMLX90640[832];
uint16_t frame[834];
float mlx90640To[768];
uint32_t pixel_data[768];

float emissivity = 0.95;
uint8_t freq = FPS8HZ;
uint8_t chess_mode = 1;

float scale_factor = 1;

float sq_size_xy;

uint8_t better_color_ramping = 0;

typedef struct
{
  uint32_t *pixels;
  unsigned int w;
  unsigned int h;
} image_t;

image_t image_orig = {pixel_data, 32, 24};
image_t image_scaled = {(uint32_t*)SDRAM_ADDR_START_SCALE, 32, 24};

#define getByte(value, n) (value >> (n*8) & 0xFF)

//

float T_MIN_param = 20;
float T_MAX_param = 35;

//

void scale_cfg()
{
  image_scaled.w = 32 * scale_factor;
  image_scaled.h = 24 * scale_factor;
  sq_size_xy = sq_size_xy_orig / scale_factor;
}

uint32_t getpixel(image_t *image, uint16_t x, uint16_t y)
{
  return image->pixels[(y*image->w)+x];
}

float lerp(float s, float e, float t)
{
  return s+(e-s)*t;
}

float blerp(float c00, float c10, float c01, float c11, float tx, float ty)
{
  return lerp(lerp(c00, c10, tx), lerp(c01, c11, tx), ty);
}

void putpixel(image_t *image, uint16_t x, uint16_t y, uint32_t color)
{
  image->pixels[(y*image->w) + x] = color;
}

void scale(image_t *src, image_t *dst, float scalex, float scaley)
{
  uint16_t newWidth = (uint16_t)src->w*scalex;
  uint16_t newHeight= (uint16_t)src->h*scaley;
  uint16_t x, y;
  for(x = 0, y = 0; y < newHeight; x++)
  {
    if(x > newWidth)
    {
        x = 0; y++;
    }
    float gx = x / (float)(newWidth) * (src->w-1);
    float gy = y / (float)(newHeight) * (src->h-1);
    uint16_t gxi = (uint16_t)gx;
    uint16_t gyi = (uint16_t)gy;
    uint32_t result=0;
    uint32_t c00 = getpixel(src, gxi, gyi);
    uint32_t c10 = getpixel(src, gxi+1, gyi);
    uint32_t c01 = getpixel(src, gxi, gyi+1);
    uint32_t c11 = getpixel(src, gxi+1, gyi+1);

    for(uint8_t i = 0; i < 3; i++)
    {
        result |= (uint8_t)blerp(getByte(c00, i), getByte(c10, i), getByte(c01, i), getByte(c11, i), gx - gxi, gy -gyi) << (8*i);
    }
    putpixel(dst,x, y, result);
  }
}

//

uint32_t FLASH_GetSector(uint32_t Address)
{
  uint32_t sector = 0;

  if((Address < ADDR_FLASH_SECTOR_1) && (Address >= ADDR_FLASH_SECTOR_0))
  {
    sector = FLASH_SECTOR_0;
  }
  else if((Address < ADDR_FLASH_SECTOR_2) && (Address >= ADDR_FLASH_SECTOR_1))
  {
    sector = FLASH_SECTOR_1;
  }
  else if((Address < ADDR_FLASH_SECTOR_3) && (Address >= ADDR_FLASH_SECTOR_2))
  {
    sector = FLASH_SECTOR_2;
  }
  else if((Address < ADDR_FLASH_SECTOR_4) && (Address >= ADDR_FLASH_SECTOR_3))
  {
    sector = FLASH_SECTOR_3;
  }
  else if((Address < ADDR_FLASH_SECTOR_5) && (Address >= ADDR_FLASH_SECTOR_4))
  {
    sector = FLASH_SECTOR_4;
  }
  else if((Address < ADDR_FLASH_SECTOR_6) && (Address >= ADDR_FLASH_SECTOR_5))
  {
    sector = FLASH_SECTOR_5;
  }
  else if((Address < ADDR_FLASH_SECTOR_7) && (Address >= ADDR_FLASH_SECTOR_6))
  {
    sector = FLASH_SECTOR_6;
  }
  else /* (Address < FLASH_END_ADDR) && (Address >= ADDR_FLASH_SECTOR_7) */
  {
    sector = FLASH_SECTOR_7;
  }
  return sector;
}

void saveCfg()
{
  FLASH_EraseInitTypeDef EraseInitStruct;
  uint32_t SECTORError = 0;

  HAL_FLASH_Unlock();

  uint32_t FirstSector = FLASH_GetSector(FLASH_USER_START_ADDR);
  uint32_t NbOfSectors = 1;

  EraseInitStruct.TypeErase     = FLASH_TYPEERASE_SECTORS;
  EraseInitStruct.VoltageRange  = FLASH_VOLTAGE_RANGE_3;
  EraseInitStruct.Sector        = FirstSector;
  EraseInitStruct.NbSectors     = NbOfSectors;

  if (HAL_FLASHEx_Erase(&EraseInitStruct, &SECTORError) != HAL_OK)
  {
    while(1);
  }

  int32_t datacfg = 0;

  datacfg = freq;
  HAL_FLASH_Program(FLASH_TYPEPROGRAM_WORD, FLASH_USER_START_ADDR, datacfg);

  datacfg = better_color_ramping;
  HAL_FLASH_Program(FLASH_TYPEPROGRAM_WORD, FLASH_USER_START_ADDR+0x4, datacfg);

  datacfg = scale_factor * 2;
  HAL_FLASH_Program(FLASH_TYPEPROGRAM_WORD, FLASH_USER_START_ADDR+0x8, datacfg);

  datacfg = (int32_t)T_MIN_param;
  HAL_FLASH_Program(FLASH_TYPEPROGRAM_WORD, FLASH_USER_START_ADDR+0xC, datacfg);

  datacfg = (int32_t)T_MAX_param;
  HAL_FLASH_Program(FLASH_TYPEPROGRAM_WORD, FLASH_USER_START_ADDR+0x10, datacfg);

  HAL_FLASH_Lock();
}

void readCfg()
{
  freq = *(__IO uint32_t *)FLASH_USER_START_ADDR;
  better_color_ramping = *(__IO uint32_t *)(FLASH_USER_START_ADDR+0x4);
  scale_factor = (float) *(__IO uint32_t *)(FLASH_USER_START_ADDR+0x8) / 2;
  T_MIN_param = (int32_t) *(__IO uint32_t *)(FLASH_USER_START_ADDR+0xC);
  T_MAX_param = (int32_t) *(__IO uint32_t *)(FLASH_USER_START_ADDR+0x10);
}

//

void TouchTimer_Init()
{
  BSP_TS_Init(LCD_GetXSize(), LCD_GetYSize());
  HAL_TIM_Base_Start_IT(&htim3);
}

void PollTouchScreen()
{
  static uint8_t ts_press_cnt;
  BSP_TS_GetState(&ts);
  if (ts.touchDetected)
  {
    TS_State.Pressed = ts.touchDetected;
    TS_State.x = ts.touchX[0];
    TS_State.y = ts.touchY[0];
    GUI_PID_StoreState(&TS_State);
    ts_press_cnt++;
  }
  else
  {
    if(ts_press_cnt)
    {
      TS_State.Pressed = 0;
      GUI_PID_StoreState(&TS_State);
      ts_press_cnt=0;

      handleTouch(ts.touchX[0], ts.touchY[0]);
    }
  }
}

//

void drawText(char *str, uint16_t x, uint16_t y, GUI_COLOR color, const GUI_FONT *font)
{
  GUI_SetColor(color);
  GUI_SetFont(font);
  GUI_DispStringAt(str, x, y);
}

uint32_t transColor(uint32_t rgb, uint8_t trans)
{
  return rgb & 0x00FFFFFF | ((uint32_t)trans << 24);
}

uint32_t temp_to_rgb_simple(float temp, float t_min, float t_max)
{
  uint8_t alpha = 0x00;
  uint8_t r = 0xFF;
  uint8_t g = 0x00;
  uint8_t b = 0x00;
  int16_t delta = 0;
  uint32_t rgb = 0;

  float k = (t_max - t_min) / 255.0f;

  delta = (uint16_t)((t_max - temp)/k);

  if (delta > 0xFF)
    delta = 0xFF;
  else
  if (delta < 0)
    delta = 0;

  r -= delta;
  b += delta;

  rgb = (alpha << 24) | (b << 16) | (g << 8) | r;

  return rgb;
}

uint32_t temp_to_rgb_better(float temp, float t_min, float t_max)
{
  uint8_t alpha = 0x00;
  uint8_t r = 0xFF;
  uint8_t g = 0xFF;
  uint8_t b = 0xFF;

  uint32_t rgb = 0;

  float dv = t_max - t_min;

  if (temp < t_min)
      temp = t_min;
  if (temp > t_max)
    temp = t_max;
  dv = t_max - t_min;

  if (temp < (t_min + 0.25 * dv))
  {
    r = 0;
    g = (4 * (temp - t_min) / dv) * 255.0;
  }
  else if (temp < (t_min + 0.5 * dv))
  {
    r = 0;
    b = (1 + 4 * (t_min + 0.25 * dv - temp) / dv) * 255.0;
  }
  else if (temp < (t_min + 0.75 * dv))
  {
    r = (4 * (temp - t_min - 0.5 * dv) / dv) * 255.0;
    b = 0;
  }
  else
  {
    g = (1 + 4 * (t_min + 0.75 * dv - temp) / dv) * 255.0;
    b = 0;
  }

  rgb = (alpha << 24) | (b << 16) | (g << 8) | r;

  return rgb;
}

uint32_t temp_to_rgb(float temp, float t_min, float t_max)
{
  if (better_color_ramping)
    return temp_to_rgb_better(temp, t_min, t_max);

  return temp_to_rgb_simple(temp, t_min, t_max);
}

void drawPixel(uint16_t col, uint16_t row, uint32_t color)
{
  uint16_t x1 = (uint16_t)(start_x + col*sq_size_xy);
  uint16_t y1 = (uint16_t)(start_y + row*sq_size_xy);
  uint16_t x2 = (uint16_t)(start_x + (col+1)*sq_size_xy);
  uint16_t y2 = (uint16_t)(start_y + (row+1)*sq_size_xy);

  GUI_SetColor(color);
  GUI_FillRect(x1, y1, x2, y2);
}

//

void drawLegend(float t_min, float t_max)
{
  uint32_t color = 0;

  float k = (t_max - t_min) / 255.0f;

  float temp = 0;

  for (uint16_t i = 0; i < 256; i++)
  {
    temp = t_max - (float)i*k;

    color = temp_to_rgb(temp, t_min, t_max);
    GUI_SetColor(color);
    GUI_FillRect(0, i+10, 10, i+11);

    if ((i % 20 == 0) || i == 255)
    {
      snprintf(str, sizeof(str), "%.1f°", temp);
      drawText(str, 15, i+8, GUI_WHITE, &GUI_Font8_1);
    }
  }
}

void setlabelTemp()
{
  float temp = 0;
  temp = mlx90640To[watch_y * image_orig.w + (image_orig.w - watch_x - 1)];
  snprintf(str, sizeof(str), "%.1f°", temp);
  temp_setlabel(str);
}

//

void handleTouch(uint16_t x, uint16_t y)
{
  uint16_t t_watch_x = (uint16_t)((x - start_x) / (sq_size_xy*scale_factor*1.0f));
  uint16_t t_watch_y = (uint16_t)((y - start_y) / (sq_size_xy*scale_factor*1.0f));

  if (t_watch_x >= image_orig.w || t_watch_y >= image_orig.h)
    return;

  watch_x = t_watch_x;
  watch_y = t_watch_y;

  setlabelTemp();

  uint16_t _x = (uint16_t)(start_x + watch_x*sq_size_xy*scale_factor*1.0f);
  uint16_t _y = (uint16_t)(start_y + watch_y*sq_size_xy*scale_factor*1.0f);
  GUI_SelectLayer(1);
  GUI_Clear();
  drawText("*", _x, _y, GUI_WHITE, &GUI_Font8_1);
  GUI_SelectLayer(0);
}

//

int FATFS_ReadData(void * p, const U8 **ppData, unsigned NumBytesReq, U32 Off)
{
  static uint32_t bytesread;
  FIL *phFile;
  phFile = (FIL*)p;
  f_lseek(phFile, Off);
  f_read(phFile, _acBuffer, NumBytesReq, (void*)&bytesread);
  *ppData = _acBuffer;
  return bytesread;
}

void drawBMP(char *name, int x0, int y0, int Num, int Denom)
{
  while(SD_busy);
  SD_busy = 1;
  f_open(&file, name, FA_READ);
  GUI_BMP_DrawScaledEx(FATFS_ReadData, &file, x0, y0, Num, Denom);
  f_close(&file);
  SD_busy = 0;
}

void generateFileNameIncBetter(char *name, char *ext, char *new_name)
{
  char newname[40] = {0};
  char digits[10] = {0};
  uint16_t index = 0;
  uint16_t temp_index = 0;

  DIR dj;

  strcat(newname, name);
  strcat(newname, "_*.");
  strcat(newname, ext);

  fr = f_findfirst(&dj, &fno, "", newname);

  while (fr == FR_OK && fno.fname[0])
  {
    temp_index = atoi(&fno.fname[strlen(name) + 1]);
    if (temp_index > index)
      index = temp_index;
    fr = f_findnext(&dj, &fno);
  }

  f_closedir(&dj);

  snprintf(digits, sizeof(digits), "_%d.", index+1);
  memset(newname, 0, sizeof(newname));

  strcat(newname, name);
  strcat(newname, digits);
  strcat(newname, ext);

  strcpy(new_name, newname);
}

void makePrintScreen()
{
  uint16_t bmp_header[27] = {0};
  uint32_t written = 0;

  uint32_t x_size = 480;
  uint32_t y_size = 272;
  uint16_t bytes_per_pixel = 4;
  uint32_t size = x_size  *y_size * bytes_per_pixel;
  uint32_t header_size = sizeof(bmp_header);
  uint32_t full_size = size + header_size;

  bmp_header[0] = 0x4D42;
  bmp_header[1] = full_size;
  bmp_header[2] = full_size >> 16;
  bmp_header[5] = header_size;
  bmp_header[7] = 0x28;
  bmp_header[9] = x_size;
  bmp_header[10] = x_size >> 16;
  bmp_header[11] = y_size;
  bmp_header[12] = y_size >> 16;
  bmp_header[13] = 0x01;
  bmp_header[14] = 8 * bytes_per_pixel;

  for (uint32_t i = 0; i < y_size; i++)
    memcpy(&(*(uint32_t*)(SDRAM_ADDR_START_SCREENSHOT + x_size*i*4)), &(*(uint32_t*)(layer0_StartAddr + size - x_size*(i+1)*4)), x_size * bytes_per_pixel);

  while(SD_busy);
  SD_busy = 1;
  generateFileNameIncBetter("screenshot", "bmp", last_name);
  f_open(&file, last_name, FA_WRITE | FA_CREATE_ALWAYS);
  f_write(&file, &bmp_header, header_size, &written);
  for (uint32_t i = 0; i < size; i += 512)
    f_write(&file, &(*(uint32_t*)(SDRAM_ADDR_START_SCREENSHOT + i)), 512, &written);
  f_close(&file);
  SD_busy = 0;
}

void cfgMLX()
{
  if (chess_mode)
    MLX90640_SetChessMode(MLX90640_ADDR);
  else
    MLX90640_SetInterleavedMode(MLX90640_ADDR);

  MLX90640_SetResolution(MLX90640_ADDR, 0x03);

  MLX90640_SetRefreshRate(MLX90640_ADDR, freq);

  MLX90640_DumpEE(MLX90640_ADDR, eeMLX90640);
  MLX90640_ExtractParameters(eeMLX90640, &mlx90640);

}

void handleMLXdata()
{
  for (uint16_t i = 0; i < image_orig.h * image_orig.w; i++)
    pixel_data[i] = temp_to_rgb(mlx90640To[i], T_MIN_param, T_MAX_param);

  scale(&image_orig, &image_scaled, scale_factor, scale_factor);

  for (int j = 0; j < image_scaled.h; j++)
    for (int i = 0; i < image_scaled.w; i++)
    {
        drawPixel(image_scaled.w - 1 - i, j, image_scaled.pixels[j * image_scaled.w + i]);
    }

  if (watch_x >= image_orig.w || watch_y >= image_orig.h)
    return;

  setlabelTemp();
}

// BME

struct bme280_dev dev;

void user_delay_ms(uint32_t period)
{
  HAL_Delay(period);
}

int8_t user_i2c_read(uint8_t id, uint8_t reg_addr, uint8_t *data, uint16_t len)
{
  HAL_I2C_Master_Transmit(&hi2c1, id, &reg_addr, 1, 1000);
  HAL_Delay(10);
  HAL_I2C_Master_Receive(&hi2c1, id, data, len, 1000);
  return 0;
}

int8_t user_i2c_write(uint8_t id, uint8_t reg_addr, uint8_t *data, uint16_t len)
{
  uint8_t * buf;
  buf = (uint8_t*)malloc(len + 1);
  buf[0] = reg_addr;
  memcpy(buf +1, data, len);
  HAL_I2C_Master_Transmit(&hi2c1, id, buf, len + 1, 1000);
  free(buf);
  return 0;
}

void BME280_data_forced_mode(struct bme280_dev *dev, struct bme280_data *comp_data)
{
    uint8_t settings_sel;

    /* Recommended mode of operation: Indoor navigation */
    dev->settings.osr_h = BME280_OVERSAMPLING_1X;
    dev->settings.osr_p = BME280_OVERSAMPLING_16X;
    dev->settings.osr_t = BME280_OVERSAMPLING_2X;
    dev->settings.filter = BME280_FILTER_COEFF_16;

    settings_sel = BME280_OSR_PRESS_SEL | BME280_OSR_TEMP_SEL | BME280_OSR_HUM_SEL | BME280_FILTER_SEL;

    bme280_set_sensor_settings(settings_sel, dev);

    bme280_set_sensor_mode(BME280_FORCED_MODE, dev);

    dev->delay_ms(40);

    bme280_get_sensor_data(BME280_ALL, comp_data, dev);
}

uint8_t BME280_API_init(uint8_t addr)
{
  //dev.dev_id = BME280_I2C_ADDR_PRIM << 1;
  //dev.dev_id = BME280_I2C_ADDR_SEC << 1;
  dev.dev_id = addr << 1;
  dev.intf = BME280_I2C_INTF;
  dev.read = user_i2c_read;
  dev.write = user_i2c_write;
  dev.delay_ms = user_delay_ms;

  return bme280_init(&dev);
}

uint8_t bmeData[32]; // BME data ascii

void handleBME280()
{
  struct bme280_data comp_data;

  BME280_data_forced_mode(&dev, &comp_data);
  snprintf((char*)bmeData, sizeof(bmeData), "   %.2f\° %.1f\%% %d P   ", (float)comp_data.temperature / 100, (float)comp_data.humidity / 1024, comp_data.pressure);
}

/* USER CODE END 0 */

int main(void)
{

  /* Enable I-Cache---------------------------------------------------------*/
  SCB_EnableICache();

  /* Enable D-Cache---------------------------------------------------------*/
  SCB_EnableDCache();

  /* MCU Configuration--------------------------------------------------------*/

  /* Reset of all peripherals, Initializes the Flash interface and the Systick. */
  HAL_Init();

  /* Configure the system clock */
  SystemClock_Config();

  /* Initialize all configured peripherals */
  MX_GPIO_Init();
  MX_CRC_Init();
  MX_I2C1_Init();
  MX_TIM3_Init();
  MX_USART1_UART_Init();
  MX_I2C3_Init();
  MX_SDMMC1_SD_Init();
  MX_USB_DEVICE_Init();
  MX_FATFS_Init();
  /* USER CODE BEGIN 2 */

  HAL_SD_Init(&hsd1);
  HAL_SD_ConfigWideBusOperation(&hsd1, SDMMC_BUS_WIDE_4B);

  f_mount(&fileSystem, SDPath, 1);

  readCfg();

  scale_cfg();

  TouchTimer_Init();

  GRAPHICS_HW_Init();
  GRAPHICS_Init();
  HAL_LTDC_EnableDither(&hltdc);

  layer0_StartAddr = hltdc.LayerCfg[0].FBStartAdress;
  layer1_StartAddr = hltdc.LayerCfg[1].FBStartAdress;

  GUI_Clear();
  GUI_SelectLayer(1);
  GUI_SetBkColor(GUI_TRANSPARENT);
  GUI_Clear();
  GUI_SelectLayer(0);

  //
  HAL_Delay(10);
  CreateWindow();
  HAL_Delay(10);
  drawLegend(T_MIN_param, T_MAX_param);
  HAL_Delay(10);

  cfgMLX();
  HAL_Delay(100);

  while(1)
  {
    HAL_PWR_EnterSLEEPMode(PWR_MAINREGULATOR_ON, PWR_SLEEPENTRY_WFI);

    GUI_Exec();

    if (HAL_GPIO_ReadPin(B_USER_GPIO_Port, B_USER_Pin))
    {
      USBD_Stop(&hUsbDeviceFS);
      makePrintScreen();
      GUI_Clear();
      drawLegend(T_MIN_param, T_MAX_param);
      drawBMP(last_name, 210, 0, 1, 2);
      drawText(last_name, 210, 200, GUI_WHITE, &GUI_Font6x8);
      USBD_Start(&hUsbDeviceFS);
    }
    if (need_to_clear)
    {
      need_to_clear = 0;

      HAL_Delay(10);

      GUI_Clear();
      drawLegend(T_MIN_param, T_MAX_param);

      HAL_Delay(10);
    }
    if (need_to_redraw)
    {
      need_to_redraw = 0;

      HAL_Delay(10);

      GUI_Clear();
      drawLegend(T_MIN_param, T_MAX_param);

      handleMLXdata();

      HAL_Delay(10);
    }
    if (need_to_save)
    {
      need_to_save = 0;

      saveCfg();
    }
    if (need_to_cfg)
    {
      need_to_cfg = 0;

      HAL_Delay(10);

      cfgMLX();

      HAL_Delay(10);
    }
    if (need_to_cfg_scale)
    {
      need_to_cfg_scale = 0;

      scale_cfg();

      HAL_Delay(10);
      handleMLXdata();
      HAL_Delay(10);
    }

    if (scan_enabled)
    {
      MLX90640_GetFrameData(MLX90640_ADDR, frame);
      float Ta = MLX90640_GetTa(frame, &mlx90640);
      float Tr = Ta - TA_SHIFT;
      MLX90640_CalculateTo(frame, &mlx90640, emissivity , Tr, mlx90640To);

      handleMLXdata();
    }
    else
    {
      BME280_API_init(BME280_I2C_ADDR_PRIM);
      handleBME280();
      drawText((char*)bmeData, 100, 100, GUI_WHITE, &GUI_Font8x16);
    }
  }

  /* USER CODE END 2 */

/* Initialise the graphical hardware */
  GRAPHICS_HW_Init();

  /* Initialise the graphical stack engine */
  GRAPHICS_Init();

  /* Graphic application */
  GRAPHICS_MainTask();

  /* Infinite loop */
  for(;;);
}

void SystemClock_Config(void)
{
  RCC_OscInitTypeDef RCC_OscInitStruct = {0};
  RCC_ClkInitTypeDef RCC_ClkInitStruct = {0};
  RCC_PeriphCLKInitTypeDef PeriphClkInitStruct = {0};

  /** Configure the main internal regulator output voltage
  */
  __HAL_RCC_PWR_CLK_ENABLE();
  __HAL_PWR_VOLTAGESCALING_CONFIG(PWR_REGULATOR_VOLTAGE_SCALE1);
  /** Initializes the CPU, AHB and APB busses clocks
  */
  RCC_OscInitStruct.OscillatorType = RCC_OSCILLATORTYPE_HSE;
  RCC_OscInitStruct.HSEState = RCC_HSE_ON;
  RCC_OscInitStruct.PLL.PLLState = RCC_PLL_ON;
  RCC_OscInitStruct.PLL.PLLSource = RCC_PLLSOURCE_HSE;
  RCC_OscInitStruct.PLL.PLLM = 25;
  RCC_OscInitStruct.PLL.PLLN = 400;
  RCC_OscInitStruct.PLL.PLLP = RCC_PLLP_DIV2;
  RCC_OscInitStruct.PLL.PLLQ = 9;
  if (HAL_RCC_OscConfig(&RCC_OscInitStruct) != HAL_OK)
  {
    Error_Handler();
  }
  /** Activate the Over-Drive mode
  */
  if (HAL_PWREx_EnableOverDrive() != HAL_OK)
  {
    Error_Handler();
  }
  /** Initializes the CPU, AHB and APB busses clocks
  */
  RCC_ClkInitStruct.ClockType = RCC_CLOCKTYPE_HCLK|RCC_CLOCKTYPE_SYSCLK
                              |RCC_CLOCKTYPE_PCLK1|RCC_CLOCKTYPE_PCLK2;
  RCC_ClkInitStruct.SYSCLKSource = RCC_SYSCLKSOURCE_PLLCLK;
  RCC_ClkInitStruct.AHBCLKDivider = RCC_SYSCLK_DIV1;
  RCC_ClkInitStruct.APB1CLKDivider = RCC_HCLK_DIV4;
  RCC_ClkInitStruct.APB2CLKDivider = RCC_HCLK_DIV2;

  if (HAL_RCC_ClockConfig(&RCC_ClkInitStruct, FLASH_LATENCY_6) != HAL_OK)
  {
    Error_Handler();
  }
  PeriphClkInitStruct.PeriphClockSelection = RCC_PERIPHCLK_LTDC|RCC_PERIPHCLK_USART1
                              |RCC_PERIPHCLK_I2C1|RCC_PERIPHCLK_I2C3
                              |RCC_PERIPHCLK_SDMMC1|RCC_PERIPHCLK_CLK48;
  PeriphClkInitStruct.PLLSAI.PLLSAIN = 192;
  PeriphClkInitStruct.PLLSAI.PLLSAIR = 6;
  PeriphClkInitStruct.PLLSAI.PLLSAIQ = 2;
  PeriphClkInitStruct.PLLSAI.PLLSAIP = RCC_PLLSAIP_DIV4;
  PeriphClkInitStruct.PLLSAIDivQ = 1;
  PeriphClkInitStruct.PLLSAIDivR = RCC_PLLSAIDIVR_4;
  PeriphClkInitStruct.Usart1ClockSelection = RCC_USART1CLKSOURCE_PCLK2;
  PeriphClkInitStruct.I2c1ClockSelection = RCC_I2C1CLKSOURCE_PCLK1;
  PeriphClkInitStruct.I2c3ClockSelection = RCC_I2C3CLKSOURCE_PCLK1;
  PeriphClkInitStruct.Clk48ClockSelection = RCC_CLK48SOURCE_PLLSAIP;
  PeriphClkInitStruct.Sdmmc1ClockSelection = RCC_SDMMC1CLKSOURCE_CLK48;
  if (HAL_RCCEx_PeriphCLKConfig(&PeriphClkInitStruct) != HAL_OK)
  {
    Error_Handler();
  }
}

static void MX_CRC_Init(void)
{

  hcrc.Instance = CRC;
  hcrc.Init.DefaultPolynomialUse = DEFAULT_POLYNOMIAL_ENABLE;
  hcrc.Init.DefaultInitValueUse = DEFAULT_INIT_VALUE_ENABLE;
  hcrc.Init.InputDataInversionMode = CRC_INPUTDATA_INVERSION_NONE;
  hcrc.Init.OutputDataInversionMode = CRC_OUTPUTDATA_INVERSION_DISABLE;
  hcrc.InputDataFormat = CRC_INPUTDATA_FORMAT_BYTES;
  if (HAL_CRC_Init(&hcrc) != HAL_OK)
  {
    Error_Handler();
  }

}

static void MX_I2C1_Init(void)
{

  hi2c1.Instance = I2C1;
  hi2c1.Init.Timing = 0x0020081F;
  hi2c1.Init.OwnAddress1 = 0;
  hi2c1.Init.AddressingMode = I2C_ADDRESSINGMODE_7BIT;
  hi2c1.Init.DualAddressMode = I2C_DUALADDRESS_DISABLE;
  hi2c1.Init.OwnAddress2 = 0;
  hi2c1.Init.OwnAddress2Masks = I2C_OA2_NOMASK;
  hi2c1.Init.GeneralCallMode = I2C_GENERALCALL_DISABLE;
  hi2c1.Init.NoStretchMode = I2C_NOSTRETCH_DISABLE;
  if (HAL_I2C_Init(&hi2c1) != HAL_OK)
  {
    Error_Handler();
  }
  /** Configure Analogue filter
  */
  if (HAL_I2CEx_ConfigAnalogFilter(&hi2c1, I2C_ANALOGFILTER_ENABLE) != HAL_OK)
  {
    Error_Handler();
  }
  /** Configure Digital filter
  */
  if (HAL_I2CEx_ConfigDigitalFilter(&hi2c1, 0) != HAL_OK)
  {
    Error_Handler();
  }

}

static void MX_I2C3_Init(void)
{

  hi2c3.Instance = I2C3;
  hi2c3.Init.Timing = 0x00C0EAFF;
  hi2c3.Init.OwnAddress1 = 0;
  hi2c3.Init.AddressingMode = I2C_ADDRESSINGMODE_7BIT;
  hi2c3.Init.DualAddressMode = I2C_DUALADDRESS_DISABLE;
  hi2c3.Init.OwnAddress2 = 0;
  hi2c3.Init.OwnAddress2Masks = I2C_OA2_NOMASK;
  hi2c3.Init.GeneralCallMode = I2C_GENERALCALL_DISABLE;
  hi2c3.Init.NoStretchMode = I2C_NOSTRETCH_DISABLE;
  if (HAL_I2C_Init(&hi2c3) != HAL_OK)
  {
    Error_Handler();
  }
  /** Configure Analogue filter
  */
  if (HAL_I2CEx_ConfigAnalogFilter(&hi2c3, I2C_ANALOGFILTER_ENABLE) != HAL_OK)
  {
    Error_Handler();
  }
  /** Configure Digital filter
  */
  if (HAL_I2CEx_ConfigDigitalFilter(&hi2c3, 0) != HAL_OK)
  {
    Error_Handler();
  }

}

static void MX_SDMMC1_SD_Init(void)
{

  hsd1.Instance = SDMMC1;
  hsd1.Init.ClockEdge = SDMMC_CLOCK_EDGE_RISING;
  hsd1.Init.ClockBypass = SDMMC_CLOCK_BYPASS_DISABLE;
  hsd1.Init.ClockPowerSave = SDMMC_CLOCK_POWER_SAVE_DISABLE;
  hsd1.Init.BusWide = SDMMC_BUS_WIDE_1B;
  hsd1.Init.HardwareFlowControl = SDMMC_HARDWARE_FLOW_CONTROL_ENABLE;
  hsd1.Init.ClockDiv = 0;

}

static void MX_TIM3_Init(void)
{

  TIM_SlaveConfigTypeDef sSlaveConfig = {0};
  TIM_MasterConfigTypeDef sMasterConfig = {0};

  htim3.Instance = TIM3;
  htim3.Init.Prescaler = 8999;
  htim3.Init.CounterMode = TIM_COUNTERMODE_UP;
  htim3.Init.Period = 499;
  htim3.Init.ClockDivision = TIM_CLOCKDIVISION_DIV1;
  htim3.Init.AutoReloadPreload = TIM_AUTORELOAD_PRELOAD_DISABLE;
  if (HAL_TIM_Base_Init(&htim3) != HAL_OK)
  {
    Error_Handler();
  }
  sSlaveConfig.SlaveMode = TIM_SLAVEMODE_RESET;
  sSlaveConfig.InputTrigger = TIM_TS_ITR0;
  if (HAL_TIM_SlaveConfigSynchro(&htim3, &sSlaveConfig) != HAL_OK)
  {
    Error_Handler();
  }
  sMasterConfig.MasterOutputTrigger = TIM_TRGO_RESET;
  sMasterConfig.MasterSlaveMode = TIM_MASTERSLAVEMODE_DISABLE;
  if (HAL_TIMEx_MasterConfigSynchronization(&htim3, &sMasterConfig) != HAL_OK)
  {
    Error_Handler();
  }

}

static void MX_USART1_UART_Init(void)
{

  huart1.Instance = USART1;
  huart1.Init.BaudRate = 115200;
  huart1.Init.WordLength = UART_WORDLENGTH_8B;
  huart1.Init.StopBits = UART_STOPBITS_1;
  huart1.Init.Parity = UART_PARITY_NONE;
  huart1.Init.Mode = UART_MODE_TX_RX;
  huart1.Init.HwFlowCtl = UART_HWCONTROL_NONE;
  huart1.Init.OverSampling = UART_OVERSAMPLING_16;
  huart1.Init.OneBitSampling = UART_ONE_BIT_SAMPLE_DISABLE;
  huart1.AdvancedInit.AdvFeatureInit = UART_ADVFEATURE_NO_INIT;
  if (HAL_UART_Init(&huart1) != HAL_OK)
  {
    Error_Handler();
  }

}

static void MX_GPIO_Init(void)
{
  GPIO_InitTypeDef GPIO_InitStruct = {0};

  /* GPIO Ports Clock Enable */
  __HAL_RCC_GPIOE_CLK_ENABLE();
  __HAL_RCC_GPIOG_CLK_ENABLE();
  __HAL_RCC_GPIOB_CLK_ENABLE();
  __HAL_RCC_GPIOD_CLK_ENABLE();
  __HAL_RCC_GPIOC_CLK_ENABLE();
  __HAL_RCC_GPIOA_CLK_ENABLE();
  __HAL_RCC_GPIOJ_CLK_ENABLE();
  __HAL_RCC_GPIOI_CLK_ENABLE();
  __HAL_RCC_GPIOK_CLK_ENABLE();
  __HAL_RCC_GPIOF_CLK_ENABLE();
  __HAL_RCC_GPIOH_CLK_ENABLE();

  /*Configure GPIO pin Output Level */
  HAL_GPIO_WritePin(OTG_FS_PowerSwitchOn_GPIO_Port, OTG_FS_PowerSwitchOn_Pin, GPIO_PIN_SET);

  /*Configure GPIO pin Output Level */
  HAL_GPIO_WritePin(GPIOI, ARDUINO_D7_Pin|ARDUINO_D8_Pin, GPIO_PIN_RESET);

  /*Configure GPIO pin Output Level */
  HAL_GPIO_WritePin(LCD_BL_CTRL_GPIO_Port, LCD_BL_CTRL_Pin, GPIO_PIN_SET);

  /*Configure GPIO pin Output Level */
  HAL_GPIO_WritePin(LCD_DISP_GPIO_Port, LCD_DISP_Pin, GPIO_PIN_SET);

  /*Configure GPIO pin Output Level */
  HAL_GPIO_WritePin(DCMI_PWR_EN_GPIO_Port, DCMI_PWR_EN_Pin, GPIO_PIN_RESET);

  /*Configure GPIO pin Output Level */
  HAL_GPIO_WritePin(GPIOG, ARDUINO_D4_Pin|ARDUINO_D2_Pin|EXT_RST_Pin, GPIO_PIN_RESET);

  /*Configure GPIO pin : OTG_HS_OverCurrent_Pin */
  GPIO_InitStruct.Pin = OTG_HS_OverCurrent_Pin;
  GPIO_InitStruct.Mode = GPIO_MODE_INPUT;
  GPIO_InitStruct.Pull = GPIO_NOPULL;
  HAL_GPIO_Init(OTG_HS_OverCurrent_GPIO_Port, &GPIO_InitStruct);

  /*Configure GPIO pin : QSPI_D2_Pin */
  GPIO_InitStruct.Pin = QSPI_D2_Pin;
  GPIO_InitStruct.Mode = GPIO_MODE_AF_PP;
  GPIO_InitStruct.Pull = GPIO_NOPULL;
  GPIO_InitStruct.Speed = GPIO_SPEED_FREQ_VERY_HIGH;
  GPIO_InitStruct.Alternate = GPIO_AF9_QUADSPI;
  HAL_GPIO_Init(QSPI_D2_GPIO_Port, &GPIO_InitStruct);

  /*Configure GPIO pins : RMII_TXD1_Pin RMII_TXD0_Pin RMII_TX_EN_Pin */
  GPIO_InitStruct.Pin = RMII_TXD1_Pin|RMII_TXD0_Pin|RMII_TX_EN_Pin;
  GPIO_InitStruct.Mode = GPIO_MODE_AF_PP;
  GPIO_InitStruct.Pull = GPIO_NOPULL;
  GPIO_InitStruct.Speed = GPIO_SPEED_FREQ_VERY_HIGH;
  GPIO_InitStruct.Alternate = GPIO_AF11_ETH;
  HAL_GPIO_Init(GPIOG, &GPIO_InitStruct);

  /*Configure GPIO pins : ULPI_D7_Pin ULPI_D6_Pin ULPI_D5_Pin ULPI_D3_Pin
                           ULPI_D2_Pin ULPI_D1_Pin ULPI_D4_Pin */
  GPIO_InitStruct.Pin = ULPI_D7_Pin|ULPI_D6_Pin|ULPI_D5_Pin|ULPI_D3_Pin
                          |ULPI_D2_Pin|ULPI_D1_Pin|ULPI_D4_Pin;
  GPIO_InitStruct.Mode = GPIO_MODE_AF_PP;
  GPIO_InitStruct.Pull = GPIO_NOPULL;
  GPIO_InitStruct.Speed = GPIO_SPEED_FREQ_VERY_HIGH;
  GPIO_InitStruct.Alternate = GPIO_AF10_OTG_HS;
  HAL_GPIO_Init(GPIOB, &GPIO_InitStruct);

  /*Configure GPIO pin : SPDIF_RX0_Pin */
  GPIO_InitStruct.Pin = SPDIF_RX0_Pin;
  GPIO_InitStruct.Mode = GPIO_MODE_AF_PP;
  GPIO_InitStruct.Pull = GPIO_NOPULL;
  GPIO_InitStruct.Speed = GPIO_SPEED_FREQ_LOW;
  GPIO_InitStruct.Alternate = GPIO_AF8_SPDIFRX;
  HAL_GPIO_Init(SPDIF_RX0_GPIO_Port, &GPIO_InitStruct);

  /*Configure GPIO pin : ARDUINO_PWM_D9_Pin */
  GPIO_InitStruct.Pin = ARDUINO_PWM_D9_Pin;
  GPIO_InitStruct.Mode = GPIO_MODE_AF_PP;
  GPIO_InitStruct.Pull = GPIO_NOPULL;
  GPIO_InitStruct.Speed = GPIO_SPEED_FREQ_VERY_HIGH;
  GPIO_InitStruct.Alternate = GPIO_AF1_TIM2;
  HAL_GPIO_Init(ARDUINO_PWM_D9_GPIO_Port, &GPIO_InitStruct);

  /*Configure GPIO pins : DCMI_D6_Pin DCMI_D7_Pin */
  GPIO_InitStruct.Pin = DCMI_D6_Pin|DCMI_D7_Pin;
  GPIO_InitStruct.Mode = GPIO_MODE_AF_PP;
  GPIO_InitStruct.Pull = GPIO_NOPULL;
  GPIO_InitStruct.Speed = GPIO_SPEED_FREQ_VERY_HIGH;
  GPIO_InitStruct.Alternate = GPIO_AF13_DCMI;
  HAL_GPIO_Init(GPIOE, &GPIO_InitStruct);

  /*Configure GPIO pin : QSPI_NCS_Pin */
  GPIO_InitStruct.Pin = QSPI_NCS_Pin;
  GPIO_InitStruct.Mode = GPIO_MODE_AF_PP;
  GPIO_InitStruct.Pull = GPIO_NOPULL;
  GPIO_InitStruct.Speed = GPIO_SPEED_FREQ_VERY_HIGH;
  GPIO_InitStruct.Alternate = GPIO_AF10_QUADSPI;
  HAL_GPIO_Init(QSPI_NCS_GPIO_Port, &GPIO_InitStruct);

  /*Configure GPIO pin : OTG_FS_VBUS_Pin */
  GPIO_InitStruct.Pin = OTG_FS_VBUS_Pin;
  GPIO_InitStruct.Mode = GPIO_MODE_INPUT;
  GPIO_InitStruct.Pull = GPIO_NOPULL;
  HAL_GPIO_Init(OTG_FS_VBUS_GPIO_Port, &GPIO_InitStruct);

  /*Configure GPIO pin : Audio_INT_Pin */
  GPIO_InitStruct.Pin = Audio_INT_Pin;
  GPIO_InitStruct.Mode = GPIO_MODE_EVT_RISING;
  GPIO_InitStruct.Pull = GPIO_NOPULL;
  HAL_GPIO_Init(Audio_INT_GPIO_Port, &GPIO_InitStruct);

  /*Configure GPIO pins : SAI2_MCLKA_Pin SAI2_SCKA_Pin SAI2_FSA_Pin SAI2_SDA_Pin */
  GPIO_InitStruct.Pin = SAI2_MCLKA_Pin|SAI2_SCKA_Pin|SAI2_FSA_Pin|SAI2_SDA_Pin;
  GPIO_InitStruct.Mode = GPIO_MODE_AF_PP;
  GPIO_InitStruct.Pull = GPIO_NOPULL;
  GPIO_InitStruct.Speed = GPIO_SPEED_FREQ_LOW;
  GPIO_InitStruct.Alternate = GPIO_AF10_SAI2;
  HAL_GPIO_Init(GPIOI, &GPIO_InitStruct);

  /*Configure GPIO pin : SAI2_SDB_Pin */
  GPIO_InitStruct.Pin = SAI2_SDB_Pin;
  GPIO_InitStruct.Mode = GPIO_MODE_AF_PP;
  GPIO_InitStruct.Pull = GPIO_NOPULL;
  GPIO_InitStruct.Speed = GPIO_SPEED_FREQ_LOW;
  GPIO_InitStruct.Alternate = GPIO_AF10_SAI2;
  HAL_GPIO_Init(SAI2_SDB_GPIO_Port, &GPIO_InitStruct);

  /*Configure GPIO pin : OTG_FS_PowerSwitchOn_Pin */
  GPIO_InitStruct.Pin = OTG_FS_PowerSwitchOn_Pin;
  GPIO_InitStruct.Mode = GPIO_MODE_OUTPUT_PP;
  GPIO_InitStruct.Pull = GPIO_NOPULL;
  GPIO_InitStruct.Speed = GPIO_SPEED_FREQ_LOW;
  HAL_GPIO_Init(OTG_FS_PowerSwitchOn_GPIO_Port, &GPIO_InitStruct);

  /*Configure GPIO pin : DCMI_D5_Pin */
  GPIO_InitStruct.Pin = DCMI_D5_Pin;
  GPIO_InitStruct.Mode = GPIO_MODE_AF_PP;
  GPIO_InitStruct.Pull = GPIO_NOPULL;
  GPIO_InitStruct.Speed = GPIO_SPEED_FREQ_VERY_HIGH;
  GPIO_InitStruct.Alternate = GPIO_AF13_DCMI;
  HAL_GPIO_Init(DCMI_D5_GPIO_Port, &GPIO_InitStruct);

  /*Configure GPIO pins : ARDUINO_D7_Pin ARDUINO_D8_Pin LCD_DISP_Pin */
  GPIO_InitStruct.Pin = ARDUINO_D7_Pin|ARDUINO_D8_Pin|LCD_DISP_Pin;
  GPIO_InitStruct.Mode = GPIO_MODE_OUTPUT_PP;
  GPIO_InitStruct.Pull = GPIO_NOPULL;
  GPIO_InitStruct.Speed = GPIO_SPEED_FREQ_LOW;
  HAL_GPIO_Init(GPIOI, &GPIO_InitStruct);

  /*Configure GPIO pin : uSD_Detect_Pin */
  GPIO_InitStruct.Pin = uSD_Detect_Pin;
  GPIO_InitStruct.Mode = GPIO_MODE_INPUT;
  GPIO_InitStruct.Pull = GPIO_NOPULL;
  HAL_GPIO_Init(uSD_Detect_GPIO_Port, &GPIO_InitStruct);

  /*Configure GPIO pin : LCD_BL_CTRL_Pin */
  GPIO_InitStruct.Pin = LCD_BL_CTRL_Pin;
  GPIO_InitStruct.Mode = GPIO_MODE_OUTPUT_PP;
  GPIO_InitStruct.Pull = GPIO_NOPULL;
  GPIO_InitStruct.Speed = GPIO_SPEED_FREQ_LOW;
  HAL_GPIO_Init(LCD_BL_CTRL_GPIO_Port, &GPIO_InitStruct);

  /*Configure GPIO pin : DCMI_VSYNC_Pin */
  GPIO_InitStruct.Pin = DCMI_VSYNC_Pin;
  GPIO_InitStruct.Mode = GPIO_MODE_AF_PP;
  GPIO_InitStruct.Pull = GPIO_NOPULL;
  GPIO_InitStruct.Speed = GPIO_SPEED_FREQ_VERY_HIGH;
  GPIO_InitStruct.Alternate = GPIO_AF13_DCMI;
  HAL_GPIO_Init(DCMI_VSYNC_GPIO_Port, &GPIO_InitStruct);

  /*Configure GPIO pin : OTG_FS_OverCurrent_Pin */
  GPIO_InitStruct.Pin = OTG_FS_OverCurrent_Pin;
  GPIO_InitStruct.Mode = GPIO_MODE_INPUT;
  GPIO_InitStruct.Pull = GPIO_NOPULL;
  HAL_GPIO_Init(OTG_FS_OverCurrent_GPIO_Port, &GPIO_InitStruct);

  /*Configure GPIO pins : TP3_Pin NC2_Pin */
  GPIO_InitStruct.Pin = TP3_Pin|NC2_Pin;
  GPIO_InitStruct.Mode = GPIO_MODE_INPUT;
  GPIO_InitStruct.Pull = GPIO_NOPULL;
  HAL_GPIO_Init(GPIOH, &GPIO_InitStruct);

  /*Configure GPIO pin : ARDUINO_SCK_D13_Pin */
  GPIO_InitStruct.Pin = ARDUINO_SCK_D13_Pin;
  GPIO_InitStruct.Mode = GPIO_MODE_AF_PP;
  GPIO_InitStruct.Pull = GPIO_NOPULL;
  GPIO_InitStruct.Speed = GPIO_SPEED_FREQ_LOW;
  GPIO_InitStruct.Alternate = GPIO_AF5_SPI2;
  HAL_GPIO_Init(ARDUINO_SCK_D13_GPIO_Port, &GPIO_InitStruct);

  /*Configure GPIO pin : DCMI_PWR_EN_Pin */
  GPIO_InitStruct.Pin = DCMI_PWR_EN_Pin;
  GPIO_InitStruct.Mode = GPIO_MODE_OUTPUT_PP;
  GPIO_InitStruct.Pull = GPIO_NOPULL;
  GPIO_InitStruct.Speed = GPIO_SPEED_FREQ_LOW;
  HAL_GPIO_Init(DCMI_PWR_EN_GPIO_Port, &GPIO_InitStruct);

  /*Configure GPIO pins : DCMI_D4_Pin DCMI_D3_Pin DCMI_D0_Pin DCMI_D2_Pin
                           DCMI_D1_Pin */
  GPIO_InitStruct.Pin = DCMI_D4_Pin|DCMI_D3_Pin|DCMI_D0_Pin|DCMI_D2_Pin
                          |DCMI_D1_Pin;
  GPIO_InitStruct.Mode = GPIO_MODE_AF_PP;
  GPIO_InitStruct.Pull = GPIO_NOPULL;
  GPIO_InitStruct.Speed = GPIO_SPEED_FREQ_VERY_HIGH;
  GPIO_InitStruct.Alternate = GPIO_AF13_DCMI;
  HAL_GPIO_Init(GPIOH, &GPIO_InitStruct);

  /*Configure GPIO pin : ARDUINO_PWM_CS_D5_Pin */
  GPIO_InitStruct.Pin = ARDUINO_PWM_CS_D5_Pin;
  GPIO_InitStruct.Mode = GPIO_MODE_AF_PP;
  GPIO_InitStruct.Pull = GPIO_NOPULL;
  GPIO_InitStruct.Speed = GPIO_SPEED_FREQ_LOW;
  GPIO_InitStruct.Alternate = GPIO_AF2_TIM5;
  HAL_GPIO_Init(ARDUINO_PWM_CS_D5_GPIO_Port, &GPIO_InitStruct);

  /*Configure GPIO pin : B_USER_Pin */
  GPIO_InitStruct.Pin = B_USER_Pin;
  GPIO_InitStruct.Mode = GPIO_MODE_INPUT;
  GPIO_InitStruct.Pull = GPIO_NOPULL;
  HAL_GPIO_Init(B_USER_GPIO_Port, &GPIO_InitStruct);

  /*Configure GPIO pin : ARDUINO_PWM_D10_Pin */
  GPIO_InitStruct.Pin = ARDUINO_PWM_D10_Pin;
  GPIO_InitStruct.Mode = GPIO_MODE_AF_PP;
  GPIO_InitStruct.Pull = GPIO_NOPULL;
  GPIO_InitStruct.Speed = GPIO_SPEED_FREQ_VERY_HIGH;
  GPIO_InitStruct.Alternate = GPIO_AF1_TIM1;
  HAL_GPIO_Init(ARDUINO_PWM_D10_GPIO_Port, &GPIO_InitStruct);

  /*Configure GPIO pin : LCD_INT_Pin */
  GPIO_InitStruct.Pin = LCD_INT_Pin;
  GPIO_InitStruct.Mode = GPIO_MODE_EVT_RISING;
  GPIO_InitStruct.Pull = GPIO_NOPULL;
  HAL_GPIO_Init(LCD_INT_GPIO_Port, &GPIO_InitStruct);

  /*Configure GPIO pins : ARDUINO_RX_D0_Pin ARDUINO_TX_D1_Pin */
  GPIO_InitStruct.Pin = ARDUINO_RX_D0_Pin|ARDUINO_TX_D1_Pin;
  GPIO_InitStruct.Mode = GPIO_MODE_AF_PP;
  GPIO_InitStruct.Pull = GPIO_NOPULL;
  GPIO_InitStruct.Speed = GPIO_SPEED_FREQ_VERY_HIGH;
  GPIO_InitStruct.Alternate = GPIO_AF8_USART6;
  HAL_GPIO_Init(GPIOC, &GPIO_InitStruct);

  /*Configure GPIO pin : ULPI_NXT_Pin */
  GPIO_InitStruct.Pin = ULPI_NXT_Pin;
  GPIO_InitStruct.Mode = GPIO_MODE_AF_PP;
  GPIO_InitStruct.Pull = GPIO_NOPULL;
  GPIO_InitStruct.Speed = GPIO_SPEED_FREQ_VERY_HIGH;
  GPIO_InitStruct.Alternate = GPIO_AF10_OTG_HS;
  HAL_GPIO_Init(ULPI_NXT_GPIO_Port, &GPIO_InitStruct);

  /*Configure GPIO pins : ARDUINO_D4_Pin ARDUINO_D2_Pin EXT_RST_Pin */
  GPIO_InitStruct.Pin = ARDUINO_D4_Pin|ARDUINO_D2_Pin|EXT_RST_Pin;
  GPIO_InitStruct.Mode = GPIO_MODE_OUTPUT_PP;
  GPIO_InitStruct.Pull = GPIO_NOPULL;
  GPIO_InitStruct.Speed = GPIO_SPEED_FREQ_LOW;
  HAL_GPIO_Init(GPIOG, &GPIO_InitStruct);

  /*Configure GPIO pins : ARDUINO_A4_Pin ARDUINO_A5_Pin ARDUINO_A1_Pin ARDUINO_A2_Pin
                           ARDUINO_A3_Pin */
  GPIO_InitStruct.Pin = ARDUINO_A4_Pin|ARDUINO_A5_Pin|ARDUINO_A1_Pin|ARDUINO_A2_Pin
                          |ARDUINO_A3_Pin;
  GPIO_InitStruct.Mode = GPIO_MODE_ANALOG;
  GPIO_InitStruct.Pull = GPIO_NOPULL;
  HAL_GPIO_Init(GPIOF, &GPIO_InitStruct);

  /*Configure GPIO pins : ULPI_STP_Pin ULPI_DIR_Pin */
  GPIO_InitStruct.Pin = ULPI_STP_Pin|ULPI_DIR_Pin;
  GPIO_InitStruct.Mode = GPIO_MODE_AF_PP;
  GPIO_InitStruct.Pull = GPIO_NOPULL;
  GPIO_InitStruct.Speed = GPIO_SPEED_FREQ_VERY_HIGH;
  GPIO_InitStruct.Alternate = GPIO_AF10_OTG_HS;
  HAL_GPIO_Init(GPIOC, &GPIO_InitStruct);

  /*Configure GPIO pins : RMII_MDC_Pin RMII_RXD0_Pin RMII_RXD1_Pin */
  GPIO_InitStruct.Pin = RMII_MDC_Pin|RMII_RXD0_Pin|RMII_RXD1_Pin;
  GPIO_InitStruct.Mode = GPIO_MODE_AF_PP;
  GPIO_InitStruct.Pull = GPIO_NOPULL;
  GPIO_InitStruct.Speed = GPIO_SPEED_FREQ_VERY_HIGH;
  GPIO_InitStruct.Alternate = GPIO_AF11_ETH;
  HAL_GPIO_Init(GPIOC, &GPIO_InitStruct);

  /*Configure GPIO pin : PB2 */
  GPIO_InitStruct.Pin = GPIO_PIN_2;
  GPIO_InitStruct.Mode = GPIO_MODE_AF_PP;
  GPIO_InitStruct.Pull = GPIO_NOPULL;
  GPIO_InitStruct.Speed = GPIO_SPEED_FREQ_VERY_HIGH;
  GPIO_InitStruct.Alternate = GPIO_AF9_QUADSPI;
  HAL_GPIO_Init(GPIOB, &GPIO_InitStruct);

  /*Configure GPIO pins : QSPI_D1_Pin QSPI_D3_Pin QSPI_D0_Pin */
  GPIO_InitStruct.Pin = QSPI_D1_Pin|QSPI_D3_Pin|QSPI_D0_Pin;
  GPIO_InitStruct.Mode = GPIO_MODE_AF_PP;
  GPIO_InitStruct.Pull = GPIO_NOPULL;
  GPIO_InitStruct.Speed = GPIO_SPEED_FREQ_VERY_HIGH;
  GPIO_InitStruct.Alternate = GPIO_AF9_QUADSPI;
  HAL_GPIO_Init(GPIOD, &GPIO_InitStruct);

  /*Configure GPIO pin : RMII_RXER_Pin */
  GPIO_InitStruct.Pin = RMII_RXER_Pin;
  GPIO_InitStruct.Mode = GPIO_MODE_INPUT;
  GPIO_InitStruct.Pull = GPIO_NOPULL;
  HAL_GPIO_Init(RMII_RXER_GPIO_Port, &GPIO_InitStruct);

  /*Configure GPIO pins : RMII_REF_CLK_Pin RMII_MDIO_Pin RMII_CRS_DV_Pin */
  GPIO_InitStruct.Pin = RMII_REF_CLK_Pin|RMII_MDIO_Pin|RMII_CRS_DV_Pin;
  GPIO_InitStruct.Mode = GPIO_MODE_AF_PP;
  GPIO_InitStruct.Pull = GPIO_NOPULL;
  GPIO_InitStruct.Speed = GPIO_SPEED_FREQ_VERY_HIGH;
  GPIO_InitStruct.Alternate = GPIO_AF11_ETH;
  HAL_GPIO_Init(GPIOA, &GPIO_InitStruct);

  /*Configure GPIO pin : ARDUINO_A0_Pin */
  GPIO_InitStruct.Pin = ARDUINO_A0_Pin;
  GPIO_InitStruct.Mode = GPIO_MODE_ANALOG;
  GPIO_InitStruct.Pull = GPIO_NOPULL;
  HAL_GPIO_Init(ARDUINO_A0_GPIO_Port, &GPIO_InitStruct);

  /*Configure GPIO pins : DCMI_HSYNC_Pin PA6 */
  GPIO_InitStruct.Pin = DCMI_HSYNC_Pin|GPIO_PIN_6;
  GPIO_InitStruct.Mode = GPIO_MODE_AF_PP;
  GPIO_InitStruct.Pull = GPIO_NOPULL;
  GPIO_InitStruct.Speed = GPIO_SPEED_FREQ_VERY_HIGH;
  GPIO_InitStruct.Alternate = GPIO_AF13_DCMI;
  HAL_GPIO_Init(GPIOA, &GPIO_InitStruct);

  /*Configure GPIO pins : ULPI_CLK_Pin ULPI_D0_Pin */
  GPIO_InitStruct.Pin = ULPI_CLK_Pin|ULPI_D0_Pin;
  GPIO_InitStruct.Mode = GPIO_MODE_AF_PP;
  GPIO_InitStruct.Pull = GPIO_NOPULL;
  GPIO_InitStruct.Speed = GPIO_SPEED_FREQ_VERY_HIGH;
  GPIO_InitStruct.Alternate = GPIO_AF10_OTG_HS;
  HAL_GPIO_Init(GPIOA, &GPIO_InitStruct);

  /*Configure GPIO pin : ARDUINO_PWM_D6_Pin */
  GPIO_InitStruct.Pin = ARDUINO_PWM_D6_Pin;
  GPIO_InitStruct.Mode = GPIO_MODE_AF_PP;
  GPIO_InitStruct.Pull = GPIO_NOPULL;
  GPIO_InitStruct.Speed = GPIO_SPEED_FREQ_LOW;
  GPIO_InitStruct.Alternate = GPIO_AF9_TIM12;
  HAL_GPIO_Init(ARDUINO_PWM_D6_GPIO_Port, &GPIO_InitStruct);

  /*Configure GPIO pins : ARDUINO_MISO_D12_Pin ARDUINO_MOSI_PWM_D11_Pin */
  GPIO_InitStruct.Pin = ARDUINO_MISO_D12_Pin|ARDUINO_MOSI_PWM_D11_Pin;
  GPIO_InitStruct.Mode = GPIO_MODE_AF_PP;
  GPIO_InitStruct.Pull = GPIO_NOPULL;
  GPIO_InitStruct.Speed = GPIO_SPEED_FREQ_LOW;
  GPIO_InitStruct.Alternate = GPIO_AF5_SPI2;
  HAL_GPIO_Init(GPIOB, &GPIO_InitStruct);

}

void HAL_TIM_PeriodElapsedCallback(TIM_HandleTypeDef *htim)
{
  if (htim->Instance == TIM6) {
    HAL_IncTick();
  }
  /* USER CODE BEGIN Callback 1 */
  if (htim->Instance == TIM3)
  {
    PollTouchScreen();
  }
  /* USER CODE END Callback 1 */
}

void Error_Handler(void)
{
}

/************************ (C) COPYRIGHT STMicroelectronics *****END OF FILE****/
